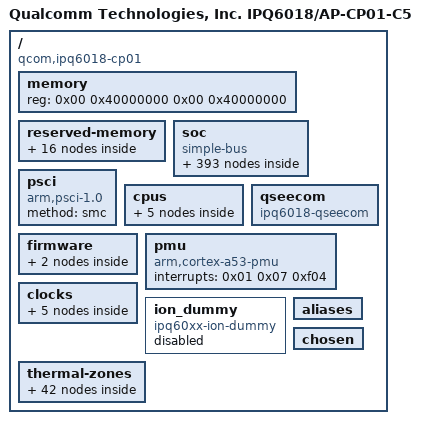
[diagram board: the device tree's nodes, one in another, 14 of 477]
/dts-v1/;

/ {
	model = "Qualcomm Technologies, Inc. IPQ6018/AP-CP01-C5";
	compatible = "qcom,ipq6018-cp01", "qcom,ipq6018";
	qcom,board-id = <0x08 0x00>;
	qcom,pmic-id = <0x00 0x00 0x00 0x00>;
	#address-cells = <0x02>;
	#size-cells = <0x02>;
	interrupt-parent = <0x01>;
	qcom,msm-id = <0x192 0x00 0x193 0x00>;

	memory {
		device_type = "memory";
		reg = <0x00 0x40000000 0x00 0x40000000>;
	};

	reserved-memory {
		#address-cells = <0x02>;
		#size-cells = <0x02>;
		ranges;

		nss@40000000 {
			no-map;
			reg = <0x00 0x40000000 0x00 0x1000000>;
		};

		uboot@4A100000 {
			no-map;
			reg = <0x00 0x4a100000 0x00 0x400000>;
		};

		sbl@4A500000 {
			no-map;
			reg = <0x00 0x4a500000 0x00 0x100000>;
		};

		tz@4A600000 {
			no-map;
			reg = <0x00 0x4a600000 0x00 0x400000>;
		};

		smem@4AA00000 {
			no-map;
			reg = <0x00 0x4aa00000 0x00 0x100000>;
			linux,phandle = <0x17>;
			phandle = <0x17>;
		};

		wcnss@4ab00000 {
			no-map;
			reg = <0x00 0x4ab00000 0x00 0x5500000>;
			linux,phandle = <0x1d>;
			phandle = <0x1d>;
		};

		q6_etr_dump@1 {
			no-map;
			reg = <0x00 0x50000000 0x00 0x100000>;
			linux,phandle = <0x1e>;
			phandle = <0x1e>;
		};

		m3_dump@50100000 {
			no-map;
			reg = <0x00 0x50100000 0x00 0x100000>;
		};

		rpm_msg_ram@0x60000 {
			no-map;
			reg = <0x00 0x60000 0x00 0x6000>;
			linux,phandle = <0x19>;
			phandle = <0x19>;
		};

		ramoops@b0000000 {
			no-map;
			reg = <0x00 0xb0000000 0x00 0x800000>;
		};

		device_last_ts@bf7fffef {
			no-map;
			reg = <0x00 0xbf7fffef 0x00 0x10>;
		};

		tzapp@49B00000 {
			no-map;
			reg = <0x00 0x49b00000 0x00 0x600000>;
		};

		qcn9000_pcie0@50200000 {
			no-map;
			reg = <0x00 0x50200000 0x00 0x2d00000>;
		};

		qcn9000_pcie1@52f00000 {
			no-map;
			reg = <0x00 0x52f00000 0x00 0x2d00000>;
		};

		dma_pool0@55c00000 {
			compatible = "shared-dma-pool";
			no-map;
			reg = <0x00 0x55c00000 0x00 0x1800000>;
			linux,phandle = <0x11>;
			phandle = <0x11>;
		};

		dma_pool1@57400000 {
			compatible = "shared-dma-pool";
			no-map;
			reg = <0x00 0x57400000 0x00 0x1800000>;
			linux,phandle = <0x12>;
			phandle = <0x12>;
		};
	};

	soc {
		#address-cells = <0x01>;
		#size-cells = <0x01>;
		ranges = <0x00 0x00 0x00 0xffffffff>;
		compatible = "simple-bus";

		wifi1@f00000 {
			compatible = "qcom,cnss-qcn9000";
			qcom,wlan-ramdump-dynamic = <0x400000>;
			status = "ok";
			mhi,max-channels = <0x1e>;
			mhi,timeout = <0x2710>;
			#address-cells = <0x01>;
			#size-cells = <0x00>;
			qrtr_node_id = <0x20>;
			qca,auto-restart;
			base-addr = "P ", "";
			m3-dump-addr = "RP", "";
			etr-addr = "R`", "";
			caldb-addr = "Rp", "";
			hremote-size = <0x2300000>;
			tgt-mem-mode = <0x00>;
			board_id = <0xa4>;
			caldb-size = <0x800000>;

			mhi_channels {

				mhi_chan@0 {
					reg = <0x00>;
					label = "LOOPBACK";
					mhi,num-elements = <0x20>;
					mhi,event-ring = <0x01>;
					mhi,chan-dir = <0x01>;
					mhi,data-type = <0x00>;
					mhi,doorbell-mode = <0x02>;
					mhi,ee = <0x14>;
				};

				mhi_chan@1 {
					reg = <0x01>;
					label = "LOOPBACK";
					mhi,num-elements = <0x20>;
					mhi,event-ring = <0x01>;
					mhi,chan-dir = <0x02>;
					mhi,data-type = <0x00>;
					mhi,doorbell-mode = <0x02>;
					mhi,ee = <0x14>;
				};

				mhi_chan@4 {
					reg = <0x04>;
					label = "DIAG";
					mhi,num-elements = <0x20>;
					mhi,event-ring = <0x01>;
					mhi,chan-dir = <0x01>;
					mhi,data-type = <0x00>;
					mhi,doorbell-mode = <0x02>;
					mhi,ee = <0x14>;
				};

				mhi_chan@5 {
					reg = <0x05>;
					label = "DIAG";
					mhi,num-elements = <0x20>;
					mhi,event-ring = <0x01>;
					mhi,chan-dir = <0x02>;
					mhi,data-type = <0x00>;
					mhi,doorbell-mode = <0x02>;
					mhi,ee = <0x14>;
				};

				mhi_chan@20 {
					reg = <0x14>;
					label = "IPCR";
					mhi,num-elements = <0x20>;
					mhi,event-ring = <0x01>;
					mhi,chan-dir = <0x01>;
					mhi,data-type = <0x01>;
					mhi,doorbell-mode = <0x02>;
					mhi,ee = <0x14>;
					mhi,auto-start;
				};

				mhi_chan@21 {
					reg = <0x15>;
					label = "IPCR";
					mhi,num-elements = <0x20>;
					mhi,event-ring = <0x01>;
					mhi,chan-dir = <0x02>;
					mhi,data-type = <0x00>;
					mhi,doorbell-mode = <0x02>;
					mhi,ee = <0x14>;
					mhi,auto-queue;
					mhi,auto-start;
				};
			};

			mhi_events {

				mhi_event@0 {
					mhi,num-elements = <0x20>;
					mhi,intmod = <0x01>;
					mhi,msi = <0x01>;
					mhi,priority = <0x01>;
					mhi,brstmode = <0x02>;
					mhi,data-type = <0x01>;
				};

				mhi_event@1 {
					mhi,num-elements = <0x100>;
					mhi,intmod = <0x01>;
					mhi,msi = <0x02>;
					mhi,priority = <0x01>;
					mhi,brstmode = <0x02>;
				};
			};

			mhi_devices {

				mhi_qrtr {
					mhi,chan = "IPCR";
					qcom,net-id = <0x00>;
				};
			};
		};

		wifi2@f00000 {
			compatible = "qcom,cnss-qcn9000";
			qcom,wlan-ramdump-dynamic = <0x400000>;
			status = "ok";
			mhi,max-channels = <0x1e>;
			mhi,timeout = <0x2710>;
			#address-cells = <0x01>;
			#size-cells = <0x00>;
			qrtr_node_id = <0x21>;
			qca,auto-restart;
			base-addr = <0x52f00000>;
			m3-dump-addr = "U ", "";
			etr-addr = "U0", "";
			caldb-addr = "U@", "";
			hremote-size = <0x2300000>;
			tgt-mem-mode = <0x00>;
			board_id = <0xa4>;
			caldb-size = <0x800000>;

			mhi_channels {

				mhi_chan@0 {
					reg = <0x00>;
					label = "LOOPBACK";
					mhi,num-elements = <0x20>;
					mhi,event-ring = <0x01>;
					mhi,chan-dir = <0x01>;
					mhi,data-type = <0x00>;
					mhi,doorbell-mode = <0x02>;
					mhi,ee = <0x14>;
				};

				mhi_chan@1 {
					reg = <0x01>;
					label = "LOOPBACK";
					mhi,num-elements = <0x20>;
					mhi,event-ring = <0x01>;
					mhi,chan-dir = <0x02>;
					mhi,data-type = <0x00>;
					mhi,doorbell-mode = <0x02>;
					mhi,ee = <0x14>;
				};

				mhi_chan@4 {
					reg = <0x04>;
					label = "DIAG";
					mhi,num-elements = <0x20>;
					mhi,event-ring = <0x01>;
					mhi,chan-dir = <0x01>;
					mhi,data-type = <0x00>;
					mhi,doorbell-mode = <0x02>;
					mhi,ee = <0x14>;
				};

				mhi_chan@5 {
					reg = <0x05>;
					label = "DIAG";
					mhi,num-elements = <0x20>;
					mhi,event-ring = <0x01>;
					mhi,chan-dir = <0x02>;
					mhi,data-type = <0x00>;
					mhi,doorbell-mode = <0x02>;
					mhi,ee = <0x14>;
				};

				mhi_chan@20 {
					reg = <0x14>;
					label = "IPCR";
					mhi,num-elements = <0x20>;
					mhi,event-ring = <0x01>;
					mhi,chan-dir = <0x01>;
					mhi,data-type = <0x01>;
					mhi,doorbell-mode = <0x02>;
					mhi,ee = <0x14>;
					mhi,auto-start;
				};

				mhi_chan@21 {
					reg = <0x15>;
					label = "IPCR";
					mhi,num-elements = <0x20>;
					mhi,event-ring = <0x01>;
					mhi,chan-dir = <0x02>;
					mhi,data-type = <0x00>;
					mhi,doorbell-mode = <0x02>;
					mhi,ee = <0x14>;
					mhi,auto-queue;
					mhi,auto-start;
				};
			};

			mhi_events {

				mhi_event@0 {
					mhi,num-elements = <0x20>;
					mhi,intmod = <0x01>;
					mhi,msi = <0x01>;
					mhi,priority = <0x01>;
					mhi,brstmode = <0x02>;
					mhi,data-type = <0x01>;
				};

				mhi_event@1 {
					mhi,num-elements = <0x100>;
					mhi,intmod = <0x01>;
					mhi,msi = <0x02>;
					mhi,priority = <0x01>;
					mhi,brstmode = <0x02>;
				};
			};

			mhi_devices {

				mhi_qrtr {
					mhi,chan = "IPCR";
					qcom,net-id = <0x00>;
				};
			};
		};

		interrupt-controller@b000000 {
			compatible = "qcom,msm-qgic2";
			interrupt-controller;
			#interrupt-cells = <0x03>;
			reg = <0xb000000 0x1000 0xb002000 0x1000>;
			linux,phandle = <0x01>;
			phandle = <0x01>;
		};

		timer {
			compatible = "arm,armv8-timer";
			interrupts = <0x01 0x02 0xf08 0x01 0x03 0xf08 0x01 0x04 0xf08 0x01 0x01 0xf08>;
			clock-frequency = <0x16e3600>;
			always-on;
		};

		gcc@1800000 {
			compatible = "qcom,gcc-ipq6018";
			reg = <0x1800000 0x80000>;
			#clock-cells = <0x01>;
			#reset-cells = <0x01>;
			linux,phandle = <0x03>;
			phandle = <0x03>;
		};

		qcom,apss_clk@b111000 {
			compatible = "qcom,apss-ipq6018";
			reg = <0xb111000 0x6000>;
			#clock-cells = <0x01>;
			#reset-cells = <0x01>;
			linux,phandle = <0x58>;
			phandle = <0x58>;
		};

		arm,smmu@1E00000 {
			compatible = "arm,smmu-v2";
			reg = <0x1e00000 0x40000>;
			#iommu-cells = <0x01>;
			#global-interrupts = <0x01>;
			qcom,skip-init;
			interrupts = <0x00 0x29 0x04 0x00 0x46 0x04 0x00 0x47 0x04 0x00 0x49 0x04 0x00 0xf0 0x04 0x00 0xf1 0x04 0x00 0xf2 0x04 0x00 0xf5 0x04 0x00 0xf6 0x04 0x00 0xf7 0x04 0x00 0xf8 0x04 0x00 0xf9 0x04 0x00 0xfa 0x04 0x00 0xfb 0x04 0x00 0xfc 0x04 0x00 0xfd 0x04 0x00 0xfe 0x04 0x00 0xff 0x04 0x00 0x35 0x04 0x00 0x36 0x04 0x00 0x3a 0x04 0x00 0x3c 0x04 0x00 0x3d 0x04 0x00 0x4c 0x04 0x00 0x4d 0x04 0x00 0x50 0x04 0x00 0x5e 0x04 0x00 0x65 0x04 0x00 0x66 0x04 0x00 0x67 0x04 0x00 0x68 0x04 0x00 0x69 0x04 0x00 0x6a 0x04>;
			status = "disabled";
			linux,phandle = <0x02>;
			phandle = <0x02>;
		};

		qcom,msm-adsprpc-mem {
			compatible = "qcom,msm-adsprpc-mem-region";
			status = "disabled";
		};

		qcom,msm_fastrpc {
			compatible = "qcom,msm-fastrpc-compute";
			qcom,rpc-latency-us = <0x263>;
			qcom,fastrpc-adsp-audio-pdr;
			qcom,fastrpc-adsp-sensors-pdr;
			qcom,fastrpc-legacy-remote-heap;
			status = "disabled";

			qcom,msm_fastrpc_compute_cb1 {
				compatible = "qcom,msm-fastrpc-compute-cb";
				label = "adsprpc-smd";
				iommus = <0x02 0x1004>;
			};

			qcom,msm_fastrpc_compute_cb2 {
				compatible = "qcom,msm-fastrpc-compute-cb";
				label = "adsprpc-smd";
				iommus = <0x02 0x1005>;
			};

			qcom,msm_fastrpc_compute_cb3 {
				compatible = "qcom,msm-fastrpc-compute-cb";
				label = "adsprpc-smd";
				iommus = <0x02 0x1006>;
			};

			qcom,msm_fastrpc_compute_cb4 {
				compatible = "qcom,msm-fastrpc-compute-cb";
				label = "adsprpc-smd";
				iommus = <0x02 0x1007>;
			};

			qcom,msm_fastrpc_compute_cb5 {
				compatible = "qcom,msm-fastrpc-compute-cb";
				label = "adsprpc-smd";
				iommus = <0x02 0x1008>;
			};

			qcom,msm_fastrpc_compute_cb6 {
				compatible = "qcom,msm-fastrpc-compute-cb";
				label = "adsprpc-smd";
				iommus = <0x02 0x1009>;
			};

			qcom,msm_fastrpc_compute_cb7 {
				compatible = "qcom,msm-fastrpc-compute-cb";
				label = "adsprpc-smd";
				iommus = <0x02 0x100a>;
			};

			qcom,msm_fastrpc_compute_cb8 {
				compatible = "qcom,msm-fastrpc-compute-cb";
				label = "adsprpc-smd";
				iommus = <0x02 0x100b>;
			};
		};

		serial@78b3000 {
			compatible = "qcom,msm-uartdm-v1.4", "qcom,msm-uartdm";
			reg = <0x78b3000 0x200>;
			interrupts = <0x00 0x134 0x04>;
			clocks = <0x03 0x54 0x03 0x43>;
			clock-names = "core", "iface";
			status = "disabled";
		};

		serial@78af000 {
			compatible = "qcom,msm-uartdm-v1.4", "qcom,msm-uartdm";
			reg = <0x78af000 0x200>;
			interrupts = <0x00 0x6b 0x04>;
			clocks = <0x03 0x50 0x03 0x43>;
			clock-names = "core", "iface";
			status = "disabled";
		};

		serial@78b0000 {
			compatible = "qcom,msm-uartdm-v1.4", "qcom,msm-uartdm";
			reg = <0x78b0000 0x200>;
			interrupts = <0x00 0x6c 0x04>;
			clocks = <0x03 0x51 0x03 0x43>;
			clock-names = "core", "iface";
			status = "ok";
			pinctrl-0 = <0x04>;
			pinctrl-names = "default";
			dmas = <0x05 0x02 0x05 0x03>;
			dma-names = "tx", "rx";
		};

		serial@78b1000 {
			compatible = "qcom,msm-uartdm-v1.4", "qcom,msm-uartdm";
			reg = <0x78b1000 0x200>;
			interrupts = <0x00 0x132 0x04>;
			clocks = <0x03 0x52 0x03 0x43>;
			clock-names = "core", "iface";
			status = "ok";
			pinctrl-0 = <0x06>;
			pinctrl-names = "default";
		};

		serial@78b2000 {
			compatible = "qcom,msm-uartdm-v1.4", "qcom,msm-uartdm";
			reg = <0x78b2000 0x200>;
			interrupts = <0x00 0x133 0x04>;
			clocks = <0x03 0x53 0x03 0x43>;
			clock-names = "core", "iface";
			status = "ok";
			pinctrl-0 = <0x07>;
			pinctrl-names = "default";
		};

		qrng@e1000 {
			compatible = "qcom,prng-ipq807x";
			reg = <0xe3000 0x1000>;
			clocks = <0x03 0x88>;
			clock-names = "core";
			status = "ok";
		};

		dma@704000 {
			compatible = "qcom,bam-v1.7.0";
			reg = <0x704000 0x20000>;
			interrupts = <0x00 0xcf 0x00>;
			clocks = <0x03 0x56>;
			clock-names = "bam_clk";
			#dma-cells = <0x01>;
			qcom,ee = <0x01>;
			qcom,controlled-remotely = <0x01>;
			qcom,config-pipe-trust-reg = <0x00>;
			linux,phandle = <0x08>;
			phandle = <0x08>;
		};

		crypto@73a000 {
			compatible = "qcom,crypto-v5.1";
			reg = <0x73a000 0x6000>;
			clocks = <0x03 0x56 0x03 0x57 0x03 0x58>;
			clock-names = "iface", "bus", "core";
			dmas = <0x08 0x02 0x08 0x03>;
			dma-names = "rx", "tx";
		};

		qcom_mdss_qpic@7980000 {
			compatible = "qcom,mdss_qpic";
			reg = <0x7980000 0x24000>;
			interrupts = <0x00 0x97 0x00>;
			clocks = <0x03 0x8a 0x03 0x89>;
			clock-names = "core", "aon";
			dmas = <0x09 0x06>;
			dma-names = "chan";
			status = "ok";
		};

		qcom_mdss_qpic_panel {
			compatible = "qcom,mdss-qpic-panel";
			label = "qpic lcd panel";
			qcom,mdss-pan-res = <0x320 0x1e0>;
			qcom,mdss-pan-bpp = <0x12>;
			qcom,refresh_rate = <0x3c>;
			status = "ok";
		};

		ssphy@78000 {
			compatible = "qcom,usb-ssphy-qmp";
			reg = <0x78000 0x45c 0x193f244 0x04 0x8af8800 0x100 0x7e000 0x18>;
			reg-names = "qmp_phy_base", "vls_clamp_reg", "qscratch_base", "ahb2phy_base";
			qcom,qmp-phy-init-seq = <0xac 0x14 0x1a 0x00 0x34 0x08 0x08 0x00 0x174 0x30 0x30 0x00 0x3c 0x06 0x06 0x00 0xb4 0x00 0x00 0x00 0xb8 0x08 0x08 0x00 0x194 0x06 0x06 0x3e8 0x19c 0x01 0x01 0x00 0x178 0x00 0x00 0x00 0xd0 0x68 0x68 0x00 0xdc 0xab 0xab 0x00 0xe0 0xaa 0xaa 0x00 0xe4 0x02 0x02 0x00 0x78 0x09 0x09 0x00 0x84 0x16 0x16 0x00 0x90 0x28 0x28 0x00 0x108 0xa0 0xa0 0x00 0x10c 0x00 0x00 0x00 0x184 0x0a 0x0a 0x00 0x4c 0xaa 0xaa 0x00 0x50 0x29 0x29 0x00 0x54 0x00 0x00 0x00 0xc8 0x00 0x00 0x00 0x18c 0x00 0x00 0x00 0xcc 0x00 0x00 0x00 0x128 0x00 0x00 0x00 0x0c 0x0a 0x0a 0x00 0x10 0x01 0x01 0x00 0x1c 0x7d 0x7d 0x00 0x20 0x01 0x01 0x00 0x14 0x00 0x00 0x00 0x18 0x00 0x00 0x00 0x24 0x0a 0x0a 0x00 0x28 0x05 0x05 0x00 0x48 0x0f 0x0f 0x00 0x70 0x0f 0x0f 0x00 0x100 0x80 0x80 0x00 0x440 0x0b 0x0b 0x00 0x4d8 0x02 0x02 0x00 0x4dc 0x6c 0x6c 0x00 0x4e0 0xbb 0xb8 0x00 0x508 0x77 0x77 0x00 0x50c 0x80 0x80 0x00 0x514 0x03 0x03 0x00 0x51c 0x16 0x16 0x00 0x448 0x75 0x75 0x00 0x454 0x00 0x00 0x00 0x40c 0x0a 0x0a 0x00 0x41c 0x06 0x06 0x00 0x510 0x00 0x00 0x00 0x268 0x45 0x45 0x00 0x2ac 0x12 0x12 0x00 0x294 0x06 0x06 0x00 0x254 0x00 0x00 0x00 0x8c8 0x83 0x83 0x00 0x8c4 0x02 0x02 0x00 0x8cc 0x09 0x09 0x00 0x8d0 0xa2 0xa2 0x00 0x8d4 0x85 0x85 0x00 0x880 0xd1 0xd1 0x00 0x884 0x1f 0x1f 0x00 0x888 0x47 0x47 0x00 0x80c 0x9f 0x9f 0x00 0x824 0x17 0x17 0x00 0x828 0x0f 0x0f 0x00 0x8b8 0x75 0x75 0x00 0x8bc 0x13 0x13 0x00 0x8b0 0x86 0x86 0x00 0x8a0 0x04 0x04 0x00 0x88c 0x44 0x44 0x00 0x870 0xe7 0xe7 0x00 0x874 0x03 0x03 0x00 0x878 0x40 0x40 0x00 0x87c 0x00 0x00 0x00 0x9d8 0x88 0x88 0x00 0xffffffff 0xffffffff 0x00 0x00>;
			qcom,qmp-phy-reg-offset = <0x988 0x98c 0x990 0x994 0x974 0x8d8 0x8dc 0x804 0x800 0x808>;
			clocks = <0x03 0x9d 0x03 0xa1>;
			clock-names = "aux_clk", "pipe_clk";
			resets = <0x03 0x27 0x03 0x28>;
			reset-names = "usb3_phy_reset", "usb3phy_phy_reset";
			status = "ok";
			linux,phandle = <0x0c>;
			phandle = <0x0c>;
		};

		qusb@79000 {
			compatible = "qcom,qusb2phy";
			reg = <0x79000 0x180 0x8af8800 0x400 0x1841030 0x04 0x8a0c12c 0x04>;
			reg-names = "qusb_phy_base", "qscratch_base", "ref_clk_addr", "usb3_guctl_addr";
			qcom,qusb-phy-init-seq = <0x14 0x00 0xf8 0x80 0xb3 0x84 0x83 0x88 0xc0 0x8c 0x30 0x08 0x79 0x0c 0x21 0x10 0x00 0x90 0x00 0x18 0x14 0x9c 0x80 0x04 0x9f 0x1c>;
			phy_type = "utmi";
			resets = <0x03 0x2b>;
			reset-names = "usb2_phy_reset";
			status = "ok";
			linux,phandle = <0x0b>;
			phandle = <0x0b>;
		};

		qusb@59000 {
			compatible = "qcom,qusb2phy";
			reg = <0x59000 0x180 0x70f8800 0x400 0x1841030 0x04 0x700c12c 0x04>;
			reg-names = "qusb_phy_base", "qscratch_base", "ref_clk_addr", "usb3_guctl_addr";
			qcom,qusb-phy-init-seq = <0x14 0x00 0xf8 0x80 0xb3 0x84 0x83 0x88 0xc0 0x8c 0x30 0x08 0x79 0x0c 0x21 0x10 0x00 0x90 0x00 0x18 0x14 0x9c 0x80 0x04 0x9f 0x1c>;
			phy_type = "utmi";
			resets = <0x03 0x2c>;
			reset-names = "usb2_phy_reset";
			status = "ok";
			linux,phandle = <0x0f>;
			phandle = <0x0f>;
		};

		dbm@0x8AF8000 {
			compatible = "qcom,usb-dbm-1p5";
			reg = <0x8af8000 0x300>;
			qcom,reset-ep-after-lpm-resume;
			linux,phandle = <0x0a>;
			phandle = <0x0a>;
		};

		usb3@8A00000 {
			compatible = "qcom,ipq6018-dwc3";
			#address-cells = <0x01>;
			#size-cells = <0x01>;
			ranges;
			reg = <0x8af8800 0x100 0x8a00000 0xcd00>;
			reg-names = "qscratch_base", "dwc3_base";
			clocks = <0x03 0xb9 0x03 0xba 0x03 0x9e 0x03 0xa2 0x03 0x9f 0x03 0xa0 0x03 0x9d 0x03 0xa1>;
			clock-names = "snoc_bus_timeout2", "sys_noc_axi", "master", "sleep", "mock_utmi", "cfg_ahb_clk", "aux_clk", "pipe_clk";
			assigned-clocks = <0x03 0xba 0x03 0x9e 0x03 0x9f>;
			assigned-clock-rates = <0x7f27450 0x7f27450 0x16e3600>;
			qca,host = <0x01>;
			qcom,usb-dbm = <0x0a>;
			status = "ok";

			dwc3@8A00000 {
				compatible = "snps,dwc3";
				reg = <0x8a00000 0xcd00>;
				interrupts = <0x00 0x8c 0x00>;
				usb-phy = <0x0b 0x0c>;
				snps,dis_ep_cache_eviction;
				tx-fifo-resize;
				snps,usb3-u1u2-disable;
				snps,nominal-elastic-buffer;
				snps,is-utmi-l1-suspend;
				snps,hird-threshold = [00];
				snps,dis_u2_susphy_quirk;
				snps,dis_u3_susphy_quirk;
				snps,quirk-ref-clock-adjustment = <0xa87f0>;
				snps,quirk-ref-clock-period = <0x29>;
				dr_mode = "host";
			};
		};

		qcom,usbbam@8B04000 {
			compatible = "qcom,usb-bam-msm";
			reg = <0x8b04000 0x17000>;
			interrupt-parent = <0x01>;
			interrupts = <0x00 0x87 0x00>;
			qcom,bam-type = <0x00>;
			qcom,usb-bam-fifo-baseaddr = <0x4a100000>;
			qcom,usb-bam-num-pipes = <0x04>;
			qcom,ignore-core-reset-ack;
			qcom,disable-clk-gating;
			qcom,usb-bam-override-threshold = <0x4001>;
			qcom,usb-bam-max-mbps-highspeed = <0x190>;
			qcom,usb-bam-max-mbps-superspeed = <0xe10>;
			qcom,reset-bam-on-connect;

			qcom,pipe0 {
				label = "ssusb-qdss-in-0";
				qcom,usb-bam-mem-type = <0x02>;
				qcom,dir = <0x01>;
				qcom,pipe-num = <0x00>;
				qcom,peer-bam = <0x00>;
				qcom,peer-bam-physical-address = <0x6064000>;
				qcom,src-bam-pipe-index = <0x00>;
				qcom,dst-bam-pipe-index = <0x00>;
				qcom,data-fifo-offset = <0x00>;
				qcom,data-fifo-size = <0xe00>;
				qcom,descriptor-fifo-offset = <0xe00>;
				qcom,descriptor-fifo-size = <0x200>;
			};
		};

		extcon_usb {
			compatible = "linux,extcon-usb-gpio";
			status = "disabled";
			pinctrl-0 = <0x0d>;
			pinctrl-names = "default";
			id-gpio = <0x0e 0x1a 0x01>;
		};

		usb2@7000000 {
			compatible = "qcom,ipq6018-dwc3";
			#address-cells = <0x01>;
			#size-cells = <0x01>;
			ranges;
			reg = <0x70f8800 0x100 0x7000000 0xcd00>;
			reg-names = "qscratch_base", "dwc3_base";
			clocks = <0x03 0xa3 0x03 0xa6 0x03 0xa4 0x03 0xa5>;
			clock-names = "master", "sleep", "mock_utmi", "cfg_ahb_clk";
			assigned-clocks = <0x03 0xa3 0x03 0xa4>;
			assigned-clock-rates = <0x7f27450 0x16e3600>;
			qca,host = <0x01>;
			status = "ok";

			dwc3@7000000 {
				compatible = "snps,dwc3";
				reg = <0x7000000 0xcd00>;
				interrupts = <0x00 0x63 0x00>;
				usb-phy = <0x0f>;
				snps,dis_ep_cache_eviction;
				tx-fifo-resize;
				snps,usb3-u1u2-disable;
				snps,nominal-elastic-buffer;
				snps,is-utmi-l1-suspend;
				snps,hird-threshold = [00];
				snps,dis_u2_susphy_quirk;
				snps,dis_u3_susphy_quirk;
				snps,quirk-ref-clock-adjustment = <0xa87f0>;
				snps,quirk-ref-clock-period = <0x29>;
				dr_mode = "host";
			};
		};

		phy@84000 {
			compatible = "qca,pcie-qmp-phy-gen3";
			reg = <0x84000 0x1000>;
			phy-type = "gen3";
			qcom,qmp-pcie-phy-init-seq = <0x840 0x03 0x1c 0x7d 0x20 0x01 0x24 0x0a 0x28 0x05 0x2c 0x08 0x30 0x04 0x3c 0x18 0x40 0x90 0x44 0x02 0x48 0x07 0x50 0x0f 0x54 0xd4 0x58 0x14 0x60 0xaa 0x64 0x29 0x74 0x0f 0xffffffff 0x01 0x80 0x09 0x84 0x09 0x88 0x16 0x8c 0x16 0x90 0x28 0x94 0x28 0xa4 0x01 0xa8 0x08 0xb0 0x20 0xc4 0x42 0xcc 0x68 0xd0 0x53 0xd8 0xab 0xdc 0xaa 0xe0 0x02 0xe4 0x55 0xe8 0x55 0xec 0x05 0x100 0xa0 0x108 0xa0 0x124 0x24 0x128 0x02 0x12c 0xb4 0x130 0x03 0x16c 0x32 0x170 0x01 0x184 0x00 0x18c 0x06 0x194 0x05 0x1b4 0x08 0x23c 0x02 0x284 0x06 0x29c 0x12 0x408 0x0c 0x414 0x02 0x434 0x7f 0x444 0x70 0x4ec 0x61 0x4f0 0x04 0x4f4 0x1e 0x4f8 0xc0 0x4fc 0x00 0x510 0x73 0x514 0x80 0x518 0x1c 0x51c 0x03 0x524 0x14 0x570 0xf0 0x574 0x01 0x578 0x2f 0x57c 0xd3 0x580 0x40 0x584 0x01 0x588 0x02 0x58c 0xc8 0x590 0x09 0x594 0xb1 0x598 0x00 0x59c 0x02 0x5a0 0xc8 0x5a4 0x09 0x5a8 0xb1 0x5b4 0x04 0x898 0x01 0x8dc 0x0d 0x96c 0x10 0x988 0xaa 0x9a4 0x01 0x9d8 0x01 0x9ec 0x01 0xc0c 0x0d 0xc14 0x07 0xc1c 0xc1 0xc40 0x01 0xc48 0x01 0xc90 0x00 0xca0 0x11 0xcbc 0x00 0xce0 0x58 0x800 0x00 0x844 0x03>;
			#phy-cells = <0x00>;
			clocks = <0x03 0x87>;
			clock-names = "pipe_clk";
			resets = <0x03 0x45 0x03 0x46>;
			reset-names = "phy", "phy_phy";
			status = "ok";
			linux,phandle = <0x10>;
			phandle = <0x10>;
		};

		pci@20000000 {
			compatible = "qcom,pcie-ipq6018";
			reg = <0x20000000 0xf1d 0x20000f20 0xa8 0x20001000 0x1000 0x80000 0x2000 0x20100000 0x1000>;
			reg-names = "dbi", "elbi", "dm_iatu", "parf", "config";
			device_type = "pci";
			linux,pci-domain = <0x00>;
			bus-range = <0x00 0xff>;
			num-lanes = <0x01>;
			#address-cells = <0x03>;
			#size-cells = <0x02>;
			phys = <0x10>;
			phy-names = "pciephy";
			ranges = <0x81000000 0x00 0x20200000 0x20200000 0x00 0x100000 0x82000000 0x00 0x20300000 0x20300000 0x00 0x10000000>;
			interrupts = <0x00 0x34 0x00 0x00 0x1a0 0x00 0x00 0x1a1 0x00 0x00 0x1a2 0x00 0x00 0x1a3 0x00 0x00 0x1a4 0x00 0x00 0x1a5 0x00 0x00 0x1a6 0x00 0x00 0x1a7 0x00 0x00 0x1a8 0x00 0x00 0x1a9 0x00 0x00 0x1aa 0x00 0x00 0x1ab 0x00 0x00 0x1ac 0x00 0x00 0x1ad 0x00 0x00 0x1ae 0x00 0x00 0x1af 0x00 0x00 0x1b0 0x00 0x00 0x1b1 0x00 0x00 0x1b2 0x00 0x00 0x1b3 0x00 0x00 0x1b4 0x00 0x00 0x1b5 0x00 0x00 0x1b6 0x00 0x00 0x1b7 0x00 0x00 0x1b8 0x00 0x00 0x1b9 0x00 0x00 0x1ba 0x00 0x00 0x1bb 0x00 0x00 0x1bc 0x00 0x00 0x1bd 0x00 0x00 0x1be 0x00 0x00 0x1bf 0x00>;
			interrupt-names = "msi", "msi_0", "msi_1", "msi_2", "msi_3", "msi_4", "msi_5", "msi_6", "msi_7", "msi_8", "msi_9", "msi_10", "msi_11", "msi_12", "msi_13", "msi_14", "msi_15", "msi_16", "msi_17", "msi_18", "msi_19", "msi_20", "msi_21", "msi_22", "msi_23", "msi_24", "msi_25", "msi_26", "msi_27", "msi_28", "msi_29", "msi_30", "msi_31";
			#interrupt-cells = <0x01>;
			interrupt-map-mask = <0x00 0x00 0x00 0x07>;
			interrupt-map = <0x00 0x00 0x00 0x01 0x01 0x00 0x4b 0x04 0x00 0x00 0x00 0x02 0x01 0x00 0x4e 0x04 0x00 0x00 0x00 0x03 0x01 0x00 0x4f 0x04 0x00 0x00 0x00 0x04 0x01 0x00 0x53 0x04>;
			clocks = <0x03 0xbb 0x03 0x85 0x03 0x86 0x03 0x83 0x03 0x84 0x03 0xc6 0x03 0xc7>;
			clock-names = "sys_noc", "axi_m", "axi_s", "ahb", "aux", "axi_bridge", "rchng";
			resets = <0x03 0x60 0x03 0x61 0x03 0x62 0x03 0x63 0x03 0x64 0x03 0x65 0x03 0x66 0x03 0x67>;
			reset-names = "pipe", "sleep", "sticky", "axi_m", "axi_s", "ahb", "axi_m_sticky", "axi_s_sticky";
			perst-gpio = <0x0e 0x3c 0x01>;
			status = "ok";
			qcom,msi-gicm-addr = <0xb00a040>;
			qcom,msi-gicm-base = <0x1c0>;

			pcie0_rp {
				reg = <0x00 0x00 0x00 0x00 0x00>;
				status = "ok";
				device_type = "pci";

				pcie_port_1 {
					reg = <0x00 0x00 0x00 0x00 0x00>;
					device_type = "pci";
					status = "ok";

					pcie_slot1 {
						reg = <0x800 0x00 0x00 0x00 0x00>;
						device_type = "pci";
						status = "ok";

						qcom,mhi@0 {
							reg = <0x00 0x00 0x00 0x00 0x00>;
							qrtr_instance_id = <0x20>;
							memory-region = <0x11>;
						};
					};

					pcie_slot2 {
						reg = <0x1000 0x00 0x00 0x00 0x00>;
						device_type = "pci";
						status = "ok";

						qcom,mhi@1 {
							reg = <0x00 0x00 0x00 0x00 0x00>;
							qrtr_instance_id = <0x21>;
							memory-region = <0x12>;
						};
					};
				};
			};
		};

		qcom,diag@0 {
			compatible = "qcom,diag";
			status = "ok";
		};

		qcom,gadget_diag@0 {
			compatible = "qcom,gadget-diag";
			status = "disabled";
		};

		dma@7884000 {
			compatible = "qcom,bam-v1.7.0";
			reg = <0x7884000 0x2b000>;
			interrupts = <0x00 0xee 0x00>;
			clocks = <0x03 0x43>;
			clock-names = "bam_clk";
			#dma-cells = <0x01>;
			qcom,ee = <0x00>;
			linux,phandle = <0x05>;
			phandle = <0x05>;
		};

		i2c@78b6000 {
			compatible = "qcom,i2c-qup-v2.2.1";
			#address-cells = <0x01>;
			#size-cells = <0x00>;
			reg = <0x78b6000 0x600>;
			interrupts = <0x00 0x60 0x04>;
			clocks = <0x03 0x43 0x03 0x46>;
			clock-names = "iface", "core";
			clock-frequency = <0x61a80>;
			dmas = <0x05 0x0f 0x05 0x0e>;
			dma-names = "rx", "tx";
			status = "disabled";
		};

		i2c@78b7000 {
			compatible = "qcom,i2c-qup-v2.2.1";
			#address-cells = <0x01>;
			#size-cells = <0x00>;
			reg = <0x78b7000 0x600>;
			interrupts = <0x00 0x61 0x04>;
			clocks = <0x03 0x43 0x03 0x48>;
			clock-names = "iface", "core";
			clock-frequency = <0x61a80>;
			dmas = <0x05 0x11 0x05 0x10>;
			dma-names = "rx", "tx";
			status = "disabled";
		};

		spi@78b5000 {
			compatible = "qcom,spi-qup-v2.2.1";
			#address-cells = <0x01>;
			#size-cells = <0x00>;
			reg = <0x78b5000 0x600>;
			interrupts = <0x00 0x5f 0x00>;
			spi-max-frequency = <0x2faf080>;
			clocks = <0x03 0x45 0x03 0x43>;
			clock-names = "core", "iface";
			dmas = <0x05 0x0c 0x05 0x0d>;
			dma-names = "tx", "rx";
			status = "ok";
			pinctrl-0 = <0x13>;
			pinctrl-names = "default";
			cs-select = <0x00>;

			m25p80@0 {
				#address-cells = <0x01>;
				#size-cells = <0x01>;
				reg = <0x00>;
				compatible = "n25q128a11";
				linux,modalias = "m25p80", "n25q128a11";
				spi-max-frequency = <0x2faf080>;
				use-default-sizes;
			};
		};

		spi@78b6000 {
			compatible = "qcom,spi-qup-v2.2.1";
			#address-cells = <0x01>;
			#size-cells = <0x00>;
			reg = <0x78b6000 0x600>;
			interrupts = <0x00 0x60 0x00>;
			spi-max-frequency = <0x2faf080>;
			clocks = <0x03 0x47 0x03 0x43>;
			clock-names = "core", "iface";
			dmas = <0x05 0x0e 0x05 0x0f>;
			dma-names = "tx", "rx";
			status = "disabled";
		};

		spi@78b9000 {
			compatible = "qcom,spi-qup-v2.2.1";
			#address-cells = <0x01>;
			#size-cells = <0x00>;
			reg = <0x78b9000 0x600>;
			interrupts = <0x00 0x12b 0x04>;
			spi-max-frequency = <0x2faf080>;
			clocks = <0x03 0x4d 0x03 0x43>;
			clock-names = "core", "iface";
			dmas = <0x05 0x14 0x05 0x15>;
			dma-names = "tx", "rx";
			status = "ok";
			pinctrl-0 = <0x14>;
			pinctrl-names = "default";
			cs-select = <0x00>;

			tpm_tis_spi@1 {
				compatible = "tcg,tpm_spi_tis";
				reg = <0x00>;
				spi-max-frequency = <0xf42400>;
			};
		};

		pwm {
			compatible = "qca,ipq6018-pwm";
			reg = <0x1941010 0x20>;
			clocks = <0x03 0xc1>;
			clock-names = "core";
			src-freq = <0x5f5e100>;
			pwm-base-index = <0x00>;
			used-pwm-indices = <0x01 0x01 0x01 0x01>;
			status = "disabled";
		};

		dcc@b3000 {
			compatible = "qca,dcc";
			status = "ok";
			reg = <0xb3000 0x1000 0xb4000 0x800 0x4a2000 0x08>;
			reg-names = "dcc-base", "dcc-ram-base", "gcnt_lo_hi";
			clocks = <0x03 0xc4>;
			clock-names = "dcc_clk";
			no_xpu_support;
			qca,save-reg;
		};

		syscon@1905000 {
			compatible = "syscon";
			reg = <0x1905000 0x8000>;
			linux,phandle = <0x15>;
			phandle = <0x15>;
		};

		hwlock@1905000 {
			compatible = "qcom,tcsr-mutex";
			syscon = <0x15 0x00 0x80>;
			#hwlock-cells = <0x01>;
			linux,phandle = <0x18>;
			phandle = <0x18>;
		};

		syscon@1945000 {
			compatible = "syscon";
			reg = <0x1945000 0xe000>;
			linux,phandle = <0x29>;
			phandle = <0x29>;
		};

		mailbox@b111000 {
			compatible = "qcom,msm8996-apcs-hmss-global";
			qcom,ipc = <0x16 0x08 0x08>;
			#mbox-cells = <0x01>;
			linux,phandle = <0x2a>;
			phandle = <0x2a>;
		};

		mailboxlpass@b111000 {
			compatible = "qcom,msm8996-apcs-hmss-global";
			qcom,ipc = <0x16 0x08 0x17>;
			#mbox-cells = <0x01>;
			linux,phandle = <0x2b>;
			phandle = <0x2b>;
		};

		mailboxrpm@b111000 {
			compatible = "qcom,msm8996-apcs-hmss-global";
			qcom,ipc = <0x16 0x08 0x00>;
			#mbox-cells = <0x01>;
			linux,phandle = <0x1a>;
			phandle = <0x1a>;
		};

		qcom,smem@4AA00000 {
			compatible = "qcom,smem";
			memory-region = <0x17>;
			hwlocks = <0x18 0x00>;
		};

		qcom,glink-smem-native-xprt-modem@4AA00000 {
			compatible = "qcom,glink-smem-native-xprt";
			reg = <0x4aa00000 0x100000 0xb111008 0x04>;
			reg-names = "smem", "irq-reg-base";
			qcom,irq-mask = <0x100>;
			interrupts = <0x00 0x141 0x01>;
			label = "mpss";
			qcom,subsys-id = <0x01>;
			smem-entry = <0x1de 0x1df 0x1e0>;
			smem-entry-names = "ch", "tx_fifo", "rx_fifo";
		};

		qcom,glink-smem-native-xprt-adsp@4AA00000 {
			compatible = "qcom,glink-smem-native-xprt";
			reg = <0x4aa00000 0x100000 0xb111008 0x04>;
			reg-names = "smem", "irq-reg-base";
			qcom,irq-mask = <0x800000>;
			interrupts = <0x00 0x18 0x01>;
			label = "adsp";
			qcom,subsys-id = <0x02>;
			smem-entry = <0x1de 0x1df 0x1e0>;
			smem-entry-names = "ch", "tx_fifo", "rx_fifo";
			status = "disabled";
		};

		qcom,glink-rpm-native-xprt@60000 {
			compatible = "qcom,glink-rpm-native-xprt";
			reg = <0x60000 0x6000 0xb111008 0x04>;
			reg-names = "msgram", "irq-reg-base";
			qcom,irq-mask = <0x01>;
			interrupts = <0x00 0xa8 0x01>;
			label = "rpm";
			qcom,subsys-id = <0x06>;
			status = "ok";
		};

		qcom,rpmsg-rpm@60000 {
			compatible = "qcom,glink-rpm";
			qcom,rpm-msg-ram = <0x19>;
			interrupts = <0x00 0xa8 0x01>;
			label = "rpm";
			qcom,subsys-id = <0x06>;
			mboxes = <0x1a 0x08>;
			status = "disabled";

			glink_edge {
				qcom,glink-channels = "rpm_requests";
				qcom,rpm-channel-type = <0x0f>;
			};
		};

		qcom,rpm-glink {
			compatible = "qcom,rpm-glink";
			qcom,glink-edge = "rpm";
			rpm-channel-name = "rpm_requests";
			qcom,rpm-channel-type = <0x0f>;
			status = "disabled";
		};

		qcom,ipc_router {
			compatible = "qcom,ipc_router";
			qcom,node-id = <0x01>;
		};

		qcom,ipc_router_modem_xprt {
			compatible = "qcom,ipc_router_glink_xprt";
			qcom,ch-name = "IPCRTR";
			qcom,xprt-remote = "mpss";
			qcom,glink-xprt = "smem";
			qcom,xprt-linkid = <0x01>;
			qcom,xprt-version = <0x01>;
			qcom,fragmented-data;
		};

		qcom,ipc_router_adsp_xprt {
			compatible = "qcom,ipc_router_glink_xprt";
			qcom,ch-name = "IPCRTR";
			qcom,xprt-remote = "adsp";
			qcom,glink-xprt = "smem";
			qcom,xprt-linkid = <0x01>;
			qcom,xprt-version = <0x01>;
			qcom,fragmented-data;
			status = "disabled";
		};

		syscon@b111000 {
			compatible = "syscon";
			reg = <0xb111000 0x1000>;
			linux,phandle = <0x16>;
			phandle = <0x16>;
		};

		smp2p-wcss {
			compatible = "qcom,smp2p";
			qcom,smem = <0x1b3 0x1ac>;
			interrupt-parent = <0x01>;
			interrupts = <0x00 0x142 0x01>;
			qcom,ipc = <0x16 0x08 0x09>;
			qcom,local-pid = <0x00>;
			qcom,remote-pid = <0x01>;

			master-kernel {
				qcom,entry-name = "master-kernel";
				qcom,smp2p-feature-ssr-ack;
				#qcom,smem-state-cells = <0x01>;
				linux,phandle = <0x1c>;
				phandle = <0x1c>;
			};

			slave-kernel {
				qcom,entry-name = "slave-kernel";
				interrupt-controller;
				#interrupt-cells = <0x02>;
				linux,phandle = <0x1b>;
				phandle = <0x1b>;
			};
		};

		smp2p-adsp {
			compatible = "qcom,smp2p";
			qcom,smem = <0x1bb 0x1ad>;
			status = "disabled";
			interrupt-parent = <0x01>;
			interrupts = <0x00 0x1a 0x01>;
			qcom,ipc = <0x16 0x08 0x15>;
			qcom,local-pid = <0x00>;
			qcom,remote-pid = <0x02>;

			master-kernel {
				qcom,entry-name = "master-kernel";
				qcom,smp2p-feature-ssr-ack;
				#qcom,smem-state-cells = <0x01>;
				linux,phandle = <0x22>;
				phandle = <0x22>;
			};

			slave-kernel {
				qcom,entry-name = "slave-kernel";
				interrupt-controller;
				#interrupt-cells = <0x02>;
				linux,phandle = <0x21>;
				phandle = <0x21>;
			};
		};

		q6v5_wcss@CD00000 {
			compatible = "qca,q6v5-wcss-rproc-ipq60xx";
			firmware = "IPQ6018/q6_fw.mdt";
			reg = <0xcd00000 0x4040 0x194f000 0x10 0x1952000 0x10 0x4ab000 0x20 0x1818000 0x110 0x1859000 0x10 0x1945000 0x10>;
			reg-names = "wcss-base", "tcsr-q6-base", "tcsr-base", "mpm-base", "gcc-wcss-bcr-base", "gcc-wcss-misc-base", "tcsr-global";
			clocks = <0x03 0xce 0x03 0xcf 0x03 0xd0 0x03 0xd1 0x03 0xcb 0x03 0xcc 0x03 0xcd 0x03 0xd2 0x03 0xd4>;
			clock-names = "wcss_axi_m_clk", "sys_noc_wcss_ahb_clk", "q6_axim_clk", "q6ss_atbm_clk", "q6ss_pclkdbg_clk", "q6_tsctr_1to2_clk", "wcss_core_tbu_clk", "wcss_q6_tbu_clk", "gcc_q6_ahb_clk";
			qca,auto-restart;
			qca,extended-intc;
			qca,sec-reset-cmd = <0x18>;
			qca,secure;
			interrupts-extended = <0x01 0x00 0x145 0x01 0x1b 0x00 0x00 0x1b 0x01 0x00 0x1b 0x03 0x00>;
			interrupt-names = "wdog", "qcom,gpio-err-fatal", "qcom,gpio-err-ready", "qcom,gpio-stop-ack";
			qcom,smem-states = <0x1c 0x00 0x1c 0x01>;
			qcom,smem-state-names = "shutdown", "stop";
			memory-region = <0x1d 0x1e>;
			linux,phandle = <0x20>;
			phandle = <0x20>;
		};

		q6v5_m3 {
			compatible = "qca,q6v5-m3-rproc";
			firmware = "IPQ6018/m3_fw.mdt";
			qca,auto-restart;
			qcom,restart-group = <0x1f 0x20>;
			linux,phandle = <0x1f>;
			phandle = <0x1f>;
		};

		q6v6_adsp@AB00000 {
			status = "disabled";
			compatible = "qca,q6v6-adsp-rproc";
			firmware = "IPQ6018/adsp.mdt";
			reg = <0xab00000 0x4040 0x181f000 0x04 0xa000000 0x48000 0x1954010 0x20>;
			reg-names = "adsp-base", "gcc-adsp-bcr-base", "adsp-cc-base", "tcsr-base";
			qca,extended-intc;
			qca,sec-reset-cmd = <0x18>;
			qca,secure;
			interrupts-extended = <0x01 0x00 0x1e 0x01 0x21 0x00 0x00 0x21 0x01 0x00 0x21 0x03 0x00>;
			interrupt-names = "wdog", "qcom,gpio-err-fatal", "qcom,gpio-err-ready", "qcom,gpio-stop-ack";
			qcom,smem-states = <0x22 0x00 0x22 0x01>;
			qcom,smem-state-names = "shutdown", "stop";
			clocks = <0x03 0xf5 0x03 0xf6 0x03 0xe4 0x03 0xe5 0x03 0xe6 0x03 0xe7 0x03 0xe8 0x03 0xe9 0x03 0xea 0x03 0xeb 0x03 0xef>;
			clock-names = "mem_noc_lpass_clk", "snoc_lpass_cfg_clk", "lpass_core_axim_clk", "lpass_snoc_cfg_clk", "lpass_q6_axim_clk", "lpass_q6_atbm_at_clk", "lpass_q6_pclkdbg_clk", "lpass_q6ss_tsctr_1to2_clk", "lpass_q6ss_trig_clk", "lpass_tbu_clk", "pcnoc_lpass_clk";
		};

		qcom,adsprpc_loader {
			compatible = "qti,adsprpc-loader";
			status = "disabled";
		};

		qcom,glink-ssr-modem {
			compatible = "qcom,glink_ssr";
			label = "q6v5-wcss";
			qcom,edge = "mpss";
			qca,no-notify-edges;
			qcom,xprt = "smem";
		};

		qcom,glink-ssr-adsp {
			compatible = "qcom,glink_ssr";
			label = "q6v6-adsp";
			qcom,edge = "adsp";
			qcom,notify-edges = <0x23>;
			qcom,xprt = "smem";
			status = "disabled";
		};

		qcom,glink-ssr-rpm {
			compatible = "qcom,glink_ssr";
			label = "rpm";
			qcom,edge = "rpm";
			qcom,no-notify-edges;
			qcom,xprt = "smem";
			linux,phandle = <0x23>;
			phandle = <0x23>;
		};

		dma@7984000 {
			compatible = "qcom,bam-v1.7.0";
			reg = <0x7984000 0x1a000>;
			interrupts = <0x00 0x92 0x00>;
			clocks = <0x03 0x89>;
			clock-names = "bam_clk";
			#dma-cells = <0x01>;
			qcom,ee = <0x00>;
			status = "ok";
			linux,phandle = <0x09>;
			phandle = <0x09>;
		};

		qcom,sps {
			compatible = "qcom,msm_sps_4k";
			qcom,pipe-attr-ee;
		};

		qpic-nand@79b0000 {
			compatible = "qcom,ebi2-nandc-bam-v1.5.0";
			reg = <0x79b0000 0x10000>;
			#address-cells = <0x01>;
			#size-cells = <0x00>;
			clocks = <0x03 0x8a 0x03 0x89>;
			clock-names = "core", "aon";
			param-read-addr-cycle = <0x01>;
			dmas = <0x09 0x00 0x09 0x01 0x09 0x02>;
			dma-names = "tx", "rx", "cmd";
			status = "disabled";

			nandcs@0 {
				compatible = "qcom,nandcs";
				reg = <0x00>;
				#address-cells = <0x01>;
				#size-cells = <0x01>;
				nand-ecc-strength = <0x04>;
				nand-ecc-step-size = <0x200>;
				nand-bus-width = <0x08>;
			};
		};

		sdcc1ice@7808000 {
			compatible = "qcom,ice";
			reg = <0x7808000 0x2000>;
			interrupts = <0x00 0x138 0x00>;
			qcom,msm-bus,vectors-KBps = <0x4e 0x200 0x00 0x00 0x4e 0x200 0x3e8 0x00>;
			qcom,bus-vector-names = "MIN", "MAX";
			qcom,instance-type = "sdcc";
			linux,phandle = <0x24>;
			phandle = <0x24>;
		};

		sdhci@7804000 {
			compatible = "qcom,sdhci-msm-v5";
			reg = <0x7804000 0x1000 0x7805000 0x1000>;
			reg-names = "hc_mem", "cmdq_mem";
			interrupts = <0x00 0x7b 0x00 0x00 0x8a 0x00>;
			interrupt-names = "hc_irq", "pwr_irq";
			qcom,bus-width = <0x08>;
			sdhc-msm-crypto = <0x24>;
			qcom,max_clk = <0xb71b000>;
			qcom,dedicated-io = <0x01>;
			qcom,vdd-voltage-level = <0x2c4020 0x2c4020>;
			qcom,vdd-current-level = <0xc8 0x8b290>;
			qcom,vdd-io-lpm-sup;
			qcom,vdd-io-voltage-level = <0x1b7740 0x1b7740>;
			qcom,vdd-io-current-level = <0xc8 0x4f588>;
			qcom,vdd-io-always-on;
			qcom,cpu-dma-latency-us = <0x2bd>;
			qcom,msm-bus,name = "sdhc1";
			qcom,msm-bus,num-cases = <0x09>;
			qcom,msm-bus,num-paths = <0x01>;
			qcom,msm-bus,vectors-KBps = <0x4e 0x200 0x00 0x00 0x4e 0x200 0x416 0xc80 0x4e 0x200 0xcc3e 0x27100 0x4e 0x200 0xff50 0x30d40 0x4e 0x200 0x1fe9e 0x61a80 0x4e 0x200 0x3fd3e 0xc3500 0x4e 0x200 0x3fd3e 0xc3500 0x4e 0x200 0x3fd3e 0xc3500 0x4e 0x200 0x146cc2 0x3e8000>;
			qcom,bus-bw-vectors-bps = <0x00 0x61a80 0x1312d00 0x17d7840 0x2faf080 0x5f5e100 0xbebc200 0x17d78400 0xffffffff>;
			clocks = <0x03 0x8b 0x03 0x8c 0x03 0xc3>;
			clock-names = "iface_clk", "core_clk", "ice_core_clk";
			qcom,ice-clk-rates = <0x9896800 0x12646790>;
			qcom,large-address-bus;
			qcom,disable-aggressive-pm;
			qcom,clk-rates = <0x61a80 0x17d7840 0x2faf080 0x5f5e100 0xb71b000>;
			qcom,bus-speed-mode = "HS200_1p8v", "DDR_1p8v";
			qcom,nonremovable;
			status = "ok";
		};

		sdhci_sd@7804000 {
			compatible = "qcom,sdhci-msm-v5";
			reg = <0x7804000 0x1000>;
			reg-names = "hc_mem";
			interrupts = <0x00 0x7b 0x00 0x00 0x8a 0x00>;
			interrupt-names = "hc_irq", "pwr_irq";
			qcom,max_clk = <0xb71b000>;
			qcom,bus-width = <0x04>;
			qcom,dedicated-io = <0x01>;
			qcom,vdd-voltage-level = <0x2d0370 0x2d0370>;
			qcom,vdd-current-level = <0x3a98 0x61a80>;
			qcom,vdd-io-lpm-sup;
			qcom,vdd-io-voltage-level = <0x1b7740 0x2d0370>;
			qcom,vdd-io-current-level = <0xc8 0x55f0>;
			qcom,vdd-io-always-on;
			qcom,cpu-dma-latency-us = <0x2bd>;
			qcom,msm-bus,name = "sdhc2";
			qcom,msm-bus,num-cases = <0x08>;
			qcom,msm-bus,num-paths = <0x01>;
			qcom,msm-bus,vectors-KBps = <0x51 0x200 0x00 0x00 0x51 0x200 0x416 0xc80 0x51 0x200 0xcc3e 0x27100 0x51 0x200 0xff50 0x30d40 0x51 0x200 0x1fe9e 0x61a80 0x51 0x200 0x3fd3e 0xc3500 0x51 0x200 0x3fd3e 0xc3500 0x51 0x200 0x146cc2 0x3e8000>;
			qcom,bus-bw-vectors-bps = <0x00 0x61a80 0x1312d00 0x17d7840 0x2faf080 0x5f5e100 0xbebc200 0xffffffff>;
			clocks = <0x03 0x8b 0x03 0x8c>;
			clock-names = "iface_clk", "core_clk";
			qcom,large-address-bus;
			qcom,disable-aggressive-pm;
			qcom,clk-rates = <0x61a80 0x17d7840 0x2faf080 0x5f5e100 0xb71b000>;
			qcom,bus-speed-mode = "HS200_1p8v", "DDR_1p8v";
			status = "disabled";
		};

		edma@3ab00000 {
			compatible = "qcom,edma";
			reg = <0x3ab00000 0xabe00>;
			reg-names = "edma-reg-base";
			qcom,txdesc-ring-start = <0x17>;
			qcom,txdesc-rings = <0x01>;
			qcom,txcmpl-ring-start = <0x17>;
			qcom,txcmpl-rings = <0x01>;
			qcom,rxfill-ring-start = <0x07>;
			qcom,rxfill-rings = <0x01>;
			qcom,rxdesc-ring-start = <0x0f>;
			qcom,rxdesc-rings = <0x01>;
			interrupts = <0x00 0x17a 0x04 0x00 0x162 0x04 0x00 0x15a 0x04 0x00 0x17b 0x04>;
			resets = <0x03 0x6d>;
			reset-names = "edma_rst";
		};

		nss-common {
			compatible = "qcom,nss-common";
			reg = <0x1868010 0x1000 0x40000000 0x1000>;
			reg-names = "nss-misc-reset", "nss-misc-reset-flag";
		};

		nss@40000000 {
			compatible = "qcom,nss";
			interrupts = <0x00 0x192 0x01 0x00 0x191 0x01 0x00 0x190 0x01 0x00 0x18f 0x01 0x00 0x18e 0x01 0x00 0x18d 0x01 0x00 0x18c 0x01 0x00 0x18b 0x01 0x00 0x18a 0x01 0x00 0x189 0x01>;
			reg = <0x39000000 0x1000 0xb111000 0x1000>;
			reg-names = "nphys", "qgic-phys";
			clocks = <0x03 0x64 0x03 0x72 0x03 0x61 0x03 0x5f 0x03 0x78 0x03 0xae 0x03 0x79 0x03 0xf4 0x03 0x5e 0x03 0x5d 0x03 0x74 0x03 0x73 0x03 0x7a 0x03 0x82 0x03 0x80 0x03 0x81 0x03 0xaf 0x03 0xf0 0x03 0xf2>;
			clock-names = "nss-noc-clk", "nss-ptp-ref-clk", "nss-csr-clk", "nss-cfg-clk", "nss-nssnoc-qosgen-ref-clk", "nss-nssnoc-snoc-clk", "nss-nssnoc-timeout-ref-clk", "nss-mem-noc-ubi32-clk", "nss-ce-axi-clk", "nss-ce-apb-clk", "nss-nssnoc-ce-axi-clk", "nss-nssnoc-ce-apb-clk", "nss-nssnoc-ahb-clk", "nss-core-clk", "nss-ahb-clk", "nss-axi-clk", "nss-nc-axi-clk", "nss-utcm-clk", "nss-snoc-nssnoc-clk";
			qcom,id = <0x00>;
			qcom,num-queue = <0x04>;
			qcom,num-irq = <0x0a>;
			qcom,num-pri = <0x04>;
			qcom,load-addr = <0x40000000>;
			qcom,low-frequency = "\v(r";
			qcom,mid-frequency = <0x2ca1c800>;
			qcom,max-frequency = <0x59439000>;
			qcom,bridge-enabled;
			qcom,ipv4-enabled;
			qcom,ipv4-reasm-enabled;
			qcom,ipv6-enabled;
			qcom,ipv6-reasm-enabled;
			qcom,wlanredirect-enabled;
			qcom,tun6rd-enabled;
			qcom,l2tpv2-enabled;
			qcom,gre-enabled;
			qcom,gre-redir-enabled;
			qcom,gre-redir-mark-enabled;
			qcom,map-t-enabled;
			qcom,portid-enabled;
			qcom,ppe-enabled;
			qcom,pppoe-enabled;
			qcom,pptp-enabled;
			qcom,tunipip6-enabled;
			qcom,shaping-enabled;
			qcom,wlan-dataplane-offload-enabled;
			qcom,vlan-enabled;
			qcom,capwap-enabled;
			qcom,dtls-enabled;
			qcom,tls-enabled;
			qcom,crypto-enabled;
			qcom,ipsec-enabled;
			qcom,qvpn-enabled;
			qcom,pvxlan-enabled;
			qcom,clmap-enabled;
			qcom,vxlan-enabled;
			qcom,match-enabled;
			qcom,mirror-enabled;
		};

		qcom,nss_crypto {
			compatible = "qcom,nss-crypto";
			#address-cells = <0x01>;
			#size-cells = <0x01>;
			qcom,max-contexts = <0x40>;
			qcom,max-context-size = <0x20>;
			ranges;
			status = "ok";

			eip197_node {
				compatible = "qcom,eip197";
				reg-names = "crypto_pbase";
				reg = <0x39800000 0x7ffff>;
				clocks = <0x03 0x60 0x03 0x75 0x03 0x5c>;
				clock-names = "crypto_clk", "crypto_nocclk", "crypto_ppeclk";
				clock-frequency = <0x00 0x11e1a300 0x00 0x11e1a300 0x00 0x11e1a300>;
				qcom,dma-mask = <0xff>;
				qcom,transform-enabled;
				qcom,aes128-cbc;
				qcom,aes192-cbc;
				qcom,aes256-cbc;
				qcom,aes128-ctr;
				qcom,aes192-ctr;
				qcom,aes256-ctr;
				qcom,aes128-ecb;
				qcom,aes192-ecb;
				qcom,aes256-ecb;
				qcom,3des-cbc;
				qcom,md5-hash;
				qcom,sha160-hash;
				qcom,sha224-hash;
				qcom,sha256-hash;
				qcom,sha384-hash;
				qcom,sha512-hash;
				qcom,md5-hmac;
				qcom,sha160-hmac;
				qcom,sha224-hmac;
				qcom,sha256-hmac;
				qcom,sha384-hmac;
				qcom,sha512-hmac;
				qcom,aes128-gcm-gmac;
				qcom,aes192-gcm-gmac;
				qcom,aes256-gcm-gmac;
				qcom,aes128-cbc-md5-hmac;
				qcom,aes128-cbc-sha160-hmac;
				qcom,aes192-cbc-md5-hmac;
				qcom,aes192-cbc-sha160-hmac;
				qcom,aes256-cbc-md5-hmac;
				qcom,aes256-cbc-sha160-hmac;
				qcom,aes128-ctr-sha160-hmac;
				qcom,aes192-ctr-sha160-hmac;
				qcom,aes256-ctr-sha160-hmac;
				qcom,aes128-ctr-md5-hmac;
				qcom,aes192-ctr-md5-hmac;
				qcom,aes256-ctr-md5-hmac;
				qcom,3des-cbc-md5-hmac;
				qcom,3des-cbc-sha160-hmac;
				qcom,aes128-cbc-sha256-hmac;
				qcom,aes192-cbc-sha256-hmac;
				qcom,aes256-cbc-sha256-hmac;
				qcom,aes128-ctr-sha256-hmac;
				qcom,aes192-ctr-sha256-hmac;
				qcom,aes256-ctr-sha256-hmac;
				qcom,3des-cbc-sha256-hmac;
				qcom,aes128-cbc-sha384-hmac;
				qcom,aes192-cbc-sha384-hmac;
				qcom,aes256-cbc-sha384-hmac;
				qcom,aes128-ctr-sha384-hmac;
				qcom,aes192-ctr-sha384-hmac;
				qcom,aes256-ctr-sha384-hmac;
				qcom,aes128-cbc-sha512-hmac;
				qcom,aes192-cbc-sha512-hmac;
				qcom,aes256-cbc-sha512-hmac;
				qcom,aes128-ctr-sha512-hmac;
				qcom,aes192-ctr-sha512-hmac;
				qcom,aes256-ctr-sha512-hmac;

				engine0 {
					reg_offset = <0x80000>;
					qcom,ifpp-enabled;
					qcom,ipue-enabled;
					qcom,ofpp-enabled;
					qcom,opue-enabled;
				};
			};
		};

		clock-controller@b188000 {
			compatible = "qcom,arm-cortex-acc";
			reg = <0xb188000 0x1000>;
			linux,phandle = <0x56>;
			phandle = <0x56>;
		};

		clock-controller@b198000 {
			compatible = "qcom,arm-cortex-acc";
			reg = <0xb198000 0x1000>;
			linux,phandle = <0x59>;
			phandle = <0x59>;
		};

		clock-controller@b1a8000 {
			compatible = "qcom,arm-cortex-acc";
			reg = <0xb1a8000 0x1000>;
			linux,phandle = <0x5a>;
			phandle = <0x5a>;
		};

		clock-controller@b1b8000 {
			compatible = "qcom,arm-cortex-acc";
			reg = <0xb1b8000 0x1000>;
			linux,phandle = <0x5b>;
			phandle = <0x5b>;
		};

		pinctrl@1000000 {
			compatible = "qcom,ipq6018-pinctrl";
			reg = <0x1000000 0x300000>;
			interrupts = <0x00 0xd0 0x00>;
			gpio-controller;
			#gpio-cells = <0x02>;
			interrupt-controller;
			#interrupt-cells = <0x02>;
			pinctrl-names = "default";
			pinctrl-0 = <0x25 0x26>;
			linux,phandle = <0x0e>;
			phandle = <0x0e>;

			uart_pins {
				linux,phandle = <0x06>;
				phandle = <0x06>;

				mux {
					pins = "gpio44", "gpio45";
					function = "blsp2_uart";
					drive-strength = <0x08>;
					bias-pull-down;
				};
			};

			uart_4_pins {
				linux,phandle = <0x07>;
				phandle = <0x07>;

				mux {
					pins = "gpio75", "gpio76";
					function = "blsp3_uart";
					drive-strength = <0x08>;
					bias-pull-down;
				};
			};

			spi_0_pins {
				linux,phandle = <0x13>;
				phandle = <0x13>;

				mux {
					pins = "gpio38", "gpio39", "gpio40", "gpio41";
					function = "blsp0_spi";
					drive-strength = <0x08>;
					bias-pull-down;
				};
			};

			spi_4_pins {
				linux,phandle = <0x14>;
				phandle = <0x14>;

				mux {
					pins = "gpio55", "gpio56", "gpio57", "gpio58";
					function = "blsp4_spi";
					drive-strength = <0x08>;
					bias-pull-down;
				};
			};

			sd_pins {

				mux {
					pins = "gpio62";
					function = "sd_card";
					drive-strength = <0x08>;
					bias-pull-up;
				};
			};

			extcon_usb_pins {
				linux,phandle = <0x0d>;
				phandle = <0x0d>;

				mux {
					pins = "gpio26";
					function = "gpio";
					drive-strength = <0x02>;
					bias-pull-down;
				};
			};

			button_pins {
				linux,phandle = <0x54>;
				phandle = <0x54>;

				wps_button {
					pins = "gpio9";
					function = "gpio";
					drive-strength = <0x08>;
					bias-pull-up;
				};

				reset_button {
					pins = "gpio19";
					function = "gpio";
					drive-strength = <0x08>;
					bias-pull-up;
				};
			};

			mdio_pinmux {
				linux,phandle = <0x28>;
				phandle = <0x28>;

				mux_0 {
					pins = "gpio64";
					function = "mdc";
					drive-strength = <0x08>;
					bias-pull-up;
				};

				mux_1 {
					pins = "gpio65";
					function = "mdio";
					drive-strength = <0x08>;
					bias-pull-up;
				};

				mux_3 {
					pins = "gpio77";
					function = "gpio";
					bias-pull-up;
				};
			};

			hsuart_pins {
				linux,phandle = <0x04>;
				phandle = <0x04>;

				mux {
					pins = "gpio71", "gpio72", "gpio69", "gpio70";
					function = "blsp1_uart";
					drive-strength = <0x08>;
					bias-disable;
				};
			};

			led_pinmux {
				linux,phandle = <0x25>;
				phandle = <0x25>;

				gps_reset_pin {
					pins = "gpio22";
					function = "gpio";
					drive-strength = <0x08>;
					bias-pull-up;
					output-high;
				};

				bt_mcuboot {
					pins = "gpio15";
					function = "gpio";
					drive-strength = <0x08>;
					bias-pull-up;
					output-high;
				};

				bt_reset_pin {
					pins = "gpio43";
					function = "gpio";
					drive-strength = <0x08>;
					bias-pull-up;
					output-low;
				};

				usb_en_pin {
					pins = "gpio67";
					function = "gpio";
					drive-strength = <0x08>;
					output-high;
				};
			};

			generic-input-pinmux {
				linux,phandle = <0x26>;
				phandle = <0x26>;

				poe_detect {
					pins = "gpio16", "gpio18", "gpio35", "gpio37", "gpio68";
					function = "gpio";
					bias-disable;
				};

				usb_current_over_limit {
					pins = "gpio66";
					function = "gpio";
					bias-disable;
				};
			};

			leds_pins {
				linux,phandle = <0x55>;
				phandle = <0x55>;

				lan1_g_led {
					pins = "gpio0";
					function = "gpio";
					drive-strength = <0x08>;
					bias-pull-down;
				};

				lan1_r_led {
					pins = "gpio1";
					function = "gpio";
					drive-strength = <0x08>;
					bias-pull-down;
				};

				lan0_g_led {
					pins = "gpio4";
					function = "gpio";
					drive-strength = <0x08>;
					bias-pull-down;
				};

				lan0_r_led {
					pins = "gpio5";
					function = "gpio";
					drive-strength = <0x08>;
					bias-pull-down;
				};

				6g_g_led {
					pins = "gpio6";
					function = "gpio";
					drive-strength = <0x08>;
					bias-pull-down;
				};

				6g_r_led {
					pins = "gpio7";
					function = "gpio";
					drive-strength = <0x08>;
					bias-pull-down;
				};

				5g_g_led {
					pins = "gpio8";
					function = "gpio";
					drive-strength = <0x08>;
					bias-pull-down;
				};

				5g_r_led {
					pins = "gpio9";
					function = "gpio";
					drive-strength = <0x08>;
					bias-pull-down;
				};

				2g_g_led {
					pins = "gpio11";
					function = "gpio";
					drive-strength = <0x08>;
					bias-pull-down;
				};

				2g_r_led {
					pins = "gpio12";
					function = "gpio";
					drive-strength = <0x08>;
					bias-pull-down;
				};

				pwr_g_led {
					pins = "gpio13";
					function = "gpio";
					drive-strength = <0x08>;
					bias-pull-down;
				};

				pwr_r_led {
					pins = "gpio14";
					function = "gpio";
					drive-strength = <0x08>;
					bias-pull-up;
				};
			};
		};

		watchdog@b017000 {
			compatible = "qcom,kpss-wdt-ipq6018";
			reg = <0xb017000 0x1000>;
			reg-names = "kpss_wdt";
			interrupt-names = "bark_irq";
			interrupts = <0x00 0x03 0x00>;
			clocks = <0x27>;
			timeout-sec = <0x1e>;
			wdt-max-timeout = <0x20>;
		};

		mdio@90000 {
			#address-cells = <0x01>;
			#size-cells = <0x01>;
			compatible = "qcom,qca-mdio", "qcom,ipq40xx-mdio";
			reg = <0x90000 0x64>;
			status = "ok";
			pinctrl-0 = <0x28>;
			pinctrl-names = "default";
			phy-reset-gpio = <0x0e 0x4d 0x00>;
			linux,phandle = <0x53>;
			phandle = <0x53>;

			ethernet-phy@0 {
				reg = <0x10>;
			};

			ethernet-phy@1 {
				reg = <0x14>;
			};
		};

		qcom_q6v5_wcss@CD00000 {
			compatible = "qcom,ipq60xx-wcss-pil";
			firmware = "IPQ6018/q6_fw.mdt";
			m3_firmware = "IPQ6018/m3_fw.mdt";
			reg = <0xcd00000 0x4040 0x4ab000 0x20>;
			reg-names = "qdsp6", "rmb";
			qca,auto-restart;
			qca,extended-intc;
			qcom,wcss-aon-reset-quirk;
			interrupts-extended = <0x01 0x00 0x145 0x01 0x1b 0x00 0x00 0x1b 0x01 0x00 0x1b 0x02 0x00 0x1b 0x03 0x00>;
			interrupt-names = "wdog", "fatal", "ready", "handover", "stop-ack";
			resets = <0x03 0x7f 0x03 0x16 0x03 0x17>;
			reset-names = "wcss_aon_reset", "wcss_reset", "wcss_q6_reset";
			qcom,halt-regs = <0x29 0xa000 0xd000 0x00>;
			qcom,smem-states = <0x1c 0x00 0x1c 0x01>;
			qcom,smem-state-names = "shutdown", "stop";
			memory-region = <0x1d 0x1e>;
			linux,phandle = <0x2c>;
			phandle = <0x2c>;

			glink-edge {
				interrupts = <0x00 0x141 0x01>;
				qcom,remote-pid = <0x01>;
				mboxes = <0x2a 0x08>;
				global_timer = "", "JP";

				rpm_requests {
					qcom,glink-channels = "IPCRTR";
				};
			};
		};

		qcom_q6v6_adsp@AB00000 {
			status = "disabled";
			compatible = "qcom,ipq6018-adsp-pil";
			interrupts-extended = <0x01 0x00 0x1e 0x01 0x21 0x00 0x00 0x21 0x01 0x00 0x21 0x02 0x00 0x21 0x03 0x00>;
			interrupt-names = "wdog", "fatal", "ready", "handover", "stop-ack";
			qcom,smem-states = <0x22 0x00 0x22 0x01>;
			qcom,smem-state-names = "shutdown", "stop";

			glink-edge {
				interrupts = <0x00 0x18 0x01>;
				qcom,remote-pid = <0x02>;
				mboxes = <0x2b 0x08>;

				rpm_requests {
					qcom,glink-channels = "IPCRTR";
				};

				qcom,msm_fastrpc_rpmsg {
					compatible = "qcom,msm-fastrpc-rpmsg";
					qcom,glink-channels = "fastrpcglink-apps-dsp";
					qcom,intents = <0x64 0x40>;
				};
			};
		};

		ess-switch@3a000000 {
			compatible = "qcom,ess-switch-ipq60xx";
			reg = <0x3a000000 0x1000000>;
			switch_access_mode = "local bus";
			clocks = <0x03 0xb7 0x03 0xb8 0x03 0x8d 0x03 0x98 0x03 0x99 0x03 0x9c 0x03 0x7b 0x03 0x7c 0x03 0x7d 0x03 0x7e 0x03 0x7f 0x03 0x70 0x03 0x6f 0x03 0x77 0x03 0x76 0x03 0x63 0x03 0x62 0x03 0x71 0x03 0x5b 0x03 0x64 0x03 0xae 0x03 0x60 0x03 0x72 0x03 0x65 0x03 0x66 0x03 0x67 0x03 0x68 0x03 0x69 0x03 0x6a 0x03 0x6b 0x03 0x6c 0x03 0x6d 0x03 0x6e 0x03 0x8e 0x03 0x8f 0x03 0x90 0x03 0x91 0x03 0x92 0x03 0x93 0x03 0x94 0x03 0x95 0x03 0x96 0x03 0x97 0x03 0x9a 0x03 0x9b 0x03 0x0c 0x03 0x0d 0x03 0xf2>;
			clock-names = "cmn_ahb_clk", "cmn_sys_clk", "uniphy0_ahb_clk", "uniphy0_sys_clk", "uniphy1_ahb_clk", "uniphy1_sys_clk", "port1_mac_clk", "port2_mac_clk", "port3_mac_clk", "port4_mac_clk", "port5_mac_clk", "nss_ppe_clk", "nss_ppe_cfg_clk", "nssnoc_ppe_clk", "nssnoc_ppe_cfg_clk", "nss_edma_clk", "nss_edma_cfg_clk", "nss_ppe_ipe_clk", "gcc_mdio_ahb_clk", "gcc_nss_noc_clk", "gcc_nssnoc_snoc_clk", "gcc_nss_crypto_clk", "gcc_nss_ptp_ref_clk", "nss_port1_rx_clk", "nss_port1_tx_clk", "nss_port2_rx_clk", "nss_port2_tx_clk", "nss_port3_rx_clk", "nss_port3_tx_clk", "nss_port4_rx_clk", "nss_port4_tx_clk", "nss_port5_rx_clk", "nss_port5_tx_clk", "uniphy0_port1_rx_clk", "uniphy0_port1_tx_clk", "uniphy0_port2_rx_clk", "uniphy0_port2_tx_clk", "uniphy0_port3_rx_clk", "uniphy0_port3_tx_clk", "uniphy0_port4_rx_clk", "uniphy0_port4_tx_clk", "uniphy0_port5_rx_clk", "uniphy0_port5_tx_clk", "uniphy1_port5_rx_clk", "uniphy1_port5_tx_clk", "nss_port5_rx_clk_src", "nss_port5_tx_clk_src", "gcc_snoc_nssnoc_clk";
			resets = <0x03 0x68 0x03 0x69 0x03 0x6a 0x03 0x6b 0x03 0x6c 0x03 0x70 0x03 0x71 0x03 0x72 0x03 0x73 0x03 0x74 0x03 0x75 0x03 0x76 0x03 0x77 0x03 0x78 0x03 0x79 0x03 0x7a 0x03 0x7b>;
			reset-names = "ppe_rst", "uniphy0_soft_rst", "uniphy0_xpcs_rst", "uniphy1_soft_rst", "uniphy1_xpcs_rst", "nss_port1_rst", "nss_port2_rst", "nss_port3_rst", "nss_port4_rst", "nss_port5_rst", "uniphy0_port1_dis", "uniphy0_port2_dis", "uniphy0_port3_dis", "uniphy0_port4_dis", "uniphy0_port5_dis", "uniphy0_port_4_5_rst", "uniphy0_port_4_rst";
			switch_cpu_bmp = <0x01>;
			switch_lan_bmp = <0x10>;
			switch_wan_bmp = <0x20>;
			switch_inner_bmp = <0xc0>;
			switch_mac_mode = <0x0f>;
			switch_mac_mode1 = <0x0f>;
			switch_mac_mode2 = <0xff>;
			bm_tick_mode = <0x00>;
			tm_tick_mode = <0x00>;

			port_scheduler_resource {

				port@0 {
					port_id = <0x00>;
					ucast_queue = <0x00 0x8f>;
					mcast_queue = <0x100 0x10f>;
					l0sp = <0x00 0x23>;
					l0cdrr = <0x00 0x2f>;
					l0edrr = <0x00 0x2f>;
					l1cdrr = <0x00 0x07>;
					l1edrr = <0x00 0x07>;
				};

				port@1 {
					port_id = <0x01>;
					ucast_queue = <0x90 0x9f>;
					mcast_queue = <0x110 0x113>;
					l0sp = <0x24 0x27>;
					l0cdrr = <0x30 0x3f>;
					l0edrr = <0x30 0x3f>;
					l1cdrr = <0x08 0x0b>;
					l1edrr = <0x08 0x0b>;
				};

				port@2 {
					port_id = <0x02>;
					ucast_queue = <0xa0 0xaf>;
					mcast_queue = <0x114 0x117>;
					l0sp = <0x28 0x2b>;
					l0cdrr = <0x40 0x4f>;
					l0edrr = <0x40 0x4f>;
					l1cdrr = <0x0c 0x0f>;
					l1edrr = <0x0c 0x0f>;
				};

				port@3 {
					port_id = <0x03>;
					ucast_queue = <0xb0 0xbf>;
					mcast_queue = <0x118 0x11b>;
					l0sp = <0x2c 0x2f>;
					l0cdrr = <0x50 0x5f>;
					l0edrr = <0x50 0x5f>;
					l1cdrr = <0x10 0x13>;
					l1edrr = <0x10 0x13>;
				};

				port@4 {
					port_id = <0x04>;
					ucast_queue = <0xc0 0xcf>;
					mcast_queue = <0x11c 0x11f>;
					l0sp = <0x30 0x33>;
					l0cdrr = <0x60 0x6f>;
					l0edrr = <0x60 0x6f>;
					l1cdrr = <0x14 0x17>;
					l1edrr = <0x14 0x17>;
				};

				port@5 {
					port_id = <0x05>;
					ucast_queue = <0xd0 0xdf>;
					mcast_queue = <0x120 0x123>;
					l0sp = <0x34 0x37>;
					l0cdrr = <0x70 0x7f>;
					l0edrr = <0x70 0x7f>;
					l1cdrr = <0x18 0x1b>;
					l1edrr = <0x18 0x1b>;
				};

				port@6 {
					port_id = <0x06>;
					ucast_queue = <0xe0 0xef>;
					mcast_queue = <0x124 0x127>;
					l0sp = <0x38 0x3b>;
					l0cdrr = <0x80 0x8f>;
					l0edrr = <0x80 0x8f>;
					l1cdrr = <0x1c 0x1f>;
					l1edrr = <0x1c 0x1f>;
				};

				port@7 {
					port_id = <0x07>;
					ucast_queue = <0xf0 0xff>;
					mcast_queue = <0x128 0x12b>;
					l0sp = <0x3c 0x3f>;
					l0cdrr = <0x90 0x9f>;
					l0edrr = <0x90 0x9f>;
					l1cdrr = <0x20 0x23>;
					l1edrr = <0x20 0x23>;
				};
			};

			port_scheduler_config {

				port@0 {
					port_id = <0x00>;

					l1scheduler {

						group@0 {
							sp = <0x00 0x01>;
							cfg = <0x00 0x00 0x00 0x00>;
						};
					};

					l0scheduler {

						group@0 {
							ucast_queue = <0x00 0x04 0x08>;
							mcast_queue = <0x100 0x104>;
							cfg = <0x00 0x00 0x00 0x00 0x00>;
						};

						group@1 {
							ucast_queue = <0x01 0x05 0x09>;
							mcast_queue = <0x101 0x105>;
							cfg = <0x00 0x01 0x01 0x01 0x01>;
						};

						group@2 {
							ucast_queue = <0x02 0x06 0x0a>;
							mcast_queue = <0x102 0x106>;
							cfg = <0x00 0x02 0x02 0x02 0x02>;
						};

						group@3 {
							ucast_queue = <0x03 0x07 0x0b>;
							mcast_queue = <0x103 0x107>;
							cfg = <0x00 0x03 0x03 0x03 0x03>;
						};
					};
				};

				port@1 {
					port_id = <0x01>;

					l1scheduler {

						group@0 {
							sp = <0x24>;
							cfg = <0x00 0x08 0x00 0x08>;
						};

						group@1 {
							sp = <0x25>;
							cfg = <0x01 0x09 0x01 0x09>;
						};
					};

					l0scheduler {

						group@0 {
							ucast_queue = <0x90>;
							ucast_loop_pri = <0x10>;
							mcast_queue = <0x110>;
							mcast_loop_pri = <0x04>;
							cfg = <0x24 0x00 0x30 0x00 0x30>;
						};
					};
				};

				port@2 {
					port_id = <0x02>;

					l1scheduler {

						group@0 {
							sp = <0x28>;
							cfg = <0x00 0x0c 0x00 0x0c>;
						};

						group@1 {
							sp = <0x29>;
							cfg = <0x01 0x0d 0x01 0x0d>;
						};
					};

					l0scheduler {

						group@0 {
							ucast_queue = <0xa0>;
							ucast_loop_pri = <0x10>;
							mcast_queue = <0x114>;
							mcast_loop_pri = <0x04>;
							cfg = <0x28 0x00 0x40 0x00 0x40>;
						};
					};
				};

				port@3 {
					port_id = <0x03>;

					l1scheduler {

						group@0 {
							sp = <0x2c>;
							cfg = <0x00 0x10 0x00 0x10>;
						};

						group@1 {
							sp = <0x2d>;
							cfg = <0x01 0x11 0x01 0x11>;
						};
					};

					l0scheduler {

						group@0 {
							ucast_queue = <0xb0>;
							ucast_loop_pri = <0x10>;
							mcast_queue = <0x118>;
							mcast_loop_pri = <0x04>;
							cfg = <0x2c 0x00 0x50 0x00 0x50>;
						};
					};
				};

				port@4 {
					port_id = <0x04>;

					l1scheduler {

						group@0 {
							sp = <0x30>;
							cfg = <0x00 0x14 0x00 0x14>;
						};

						group@1 {
							sp = <0x31>;
							cfg = <0x01 0x15 0x01 0x15>;
						};
					};

					l0scheduler {

						group@0 {
							ucast_queue = <0xc0>;
							ucast_loop_pri = <0x10>;
							mcast_queue = <0x11c>;
							mcast_loop_pri = <0x04>;
							cfg = <0x30 0x00 0x60 0x00 0x60>;
						};
					};
				};

				port@5 {
					port_id = <0x05>;

					l1scheduler {

						group@0 {
							sp = <0x34>;
							cfg = <0x00 0x18 0x00 0x18>;
						};

						group@1 {
							sp = <0x35>;
							cfg = <0x01 0x19 0x01 0x19>;
						};
					};

					l0scheduler {

						group@0 {
							ucast_queue = <0xd0>;
							ucast_loop_pri = <0x10>;
							mcast_queue = <0x120>;
							mcast_loop_pri = <0x04>;
							cfg = <0x34 0x00 0x70 0x00 0x70>;
						};
					};
				};

				port@6 {
					port_id = <0x06>;

					l1scheduler {

						group@0 {
							sp = <0x38>;
							cfg = <0x00 0x1c 0x00 0x1c>;
						};

						group@1 {
							sp = <0x39>;
							cfg = <0x01 0x1d 0x01 0x1d>;
						};
					};

					l0scheduler {

						group@0 {
							ucast_queue = <0xe0>;
							ucast_loop_pri = <0x10>;
							mcast_queue = <0x124>;
							mcast_loop_pri = <0x04>;
							cfg = <0x38 0x00 0x80 0x00 0x80>;
						};
					};
				};

				port@7 {
					port_id = <0x07>;

					l1scheduler {

						group@0 {
							sp = <0x3c>;
							cfg = <0x00 0x20 0x00 0x20>;
						};

						group@1 {
							sp = <0x3d>;
							cfg = <0x01 0x21 0x01 0x21>;
						};
					};

					l0scheduler {

						group@0 {
							ucast_queue = <0xf0>;
							ucast_loop_pri = <0x10>;
							mcast_queue = <0x128>;
							cfg = <0x3c 0x00 0x90 0x00 0x90>;
						};
					};
				};
			};

			qcom,port_phyinfo {

				port@4 {
					port_id = <0x04>;
					phy_address = <0x10>;
					port_mac_sel = "QGMAC_PORT";
				};

				port@5 {
					port_id = <0x05>;
					phy_address = <0x14>;
					port_mac_sel = "QGMAC_PORT";
				};
			};
		};

		ess-uniphy@7a00000 {
			compatible = "qcom,ess-uniphy";
			reg = <0x7a00000 0x30000>;
			uniphy_access_mode = "local bus";
		};

		wifi@c000000 {
			compatible = "qcom,cnss-qca6018", "qcom,ipq6018-wifi";
			reg = <0xc000000 0x1000000>;
			qcom,hw-mode-id = <0x01>;
			qcom,tgt-mem-mode = <0x00>;
			qcom,bdf-addr = <0x4abc0000 0x4abc0000 0x4abc0000 0x00 0x00>;
			qcom,caldb-addr = <0x4b500000 0x4b500000 0x4b500000 0x00 0x00>;
			qcom,caldb-size = <0x480000>;
			qcom,rproc = <0x2c>;
			interrupts = <0x00 0x140 0x01 0x00 0x13f 0x01 0x00 0x13e 0x01 0x00 0x13c 0x01 0x00 0x13b 0x01 0x00 0x13a 0x01 0x00 0x137 0x01 0x00 0x136 0x01 0x00 0x19b 0x01 0x00 0x19a 0x01 0x00 0x28 0x01 0x00 0x27 0x01 0x00 0x12e 0x01 0x00 0x12d 0x01 0x00 0x25 0x01 0x00 0x24 0x01 0x00 0x128 0x01 0x00 0x127 0x01 0x00 0x126 0x01 0x00 0x125 0x01 0x00 0x124 0x01 0x00 0x123 0x01 0x00 0x122 0x01 0x00 0x121 0x01 0x00 0x120 0x01 0x00 0xef 0x01 0x00 0xec 0x01 0x00 0xeb 0x01 0x00 0xea 0x01 0x00 0xe9 0x01 0x00 0xe8 0x01 0x00 0xe7 0x01 0x00 0xe6 0x01 0x00 0xe5 0x01 0x00 0xe4 0x01 0x00 0xe0 0x01 0x00 0xdf 0x01 0x00 0xcb 0x01 0x00 0xb7 0x01 0x00 0xb4 0x01 0x00 0xb3 0x01 0x00 0xb2 0x01 0x00 0xb1 0x01 0x00 0xb0 0x01 0x00 0xa3 0x01 0x00 0xa2 0x01 0x00 0xa0 0x01 0x00 0x9f 0x01 0x00 0x9e 0x01 0x00 0x9d 0x01 0x00 0x9c 0x01>;
			interrupt-names = "misc-pulse1", "misc-latch", "sw-exception", "ce0", "ce1", "ce2", "ce3", "ce4", "ce5", "ce6", "ce7", "ce8", "ce9", "ce10", "ce11", "host2wbm-desc-feed", "host2reo-re-injection", "host2reo-command", "host2rxdma-monitor-ring3", "host2rxdma-monitor-ring2", "host2rxdma-monitor-ring1", "reo2ost-exception", "wbm2host-rx-release", "reo2host-status", "reo2host-destination-ring4", "reo2host-destination-ring3", "reo2host-destination-ring2", "reo2host-destination-ring1", "rxdma2host-monitor-destination-mac3", "rxdma2host-monitor-destination-mac2", "rxdma2host-monitor-destination-mac1", "ppdu-end-interrupts-mac3", "ppdu-end-interrupts-mac2", "ppdu-end-interrupts-mac1", "rxdma2host-monitor-status-ring-mac3", "rxdma2host-monitor-status-ring-mac2", "rxdma2host-monitor-status-ring-mac1", "host2rxdma-host-buf-ring-mac3", "host2rxdma-host-buf-ring-mac2", "host2rxdma-host-buf-ring-mac1", "rxdma2host-destination-ring-mac3", "rxdma2host-destination-ring-mac2", "rxdma2host-destination-ring-mac1", "host2tcl-input-ring4", "host2tcl-input-ring3", "host2tcl-input-ring2", "host2tcl-input-ring1", "wbm2host-tx-completions-ring3", "wbm2host-tx-completions-ring2", "wbm2host-tx-completions-ring1", "tcl2host-status-ring";
			status = "ok";
			qcom,pta-num = <0x00>;
			qcom,coex-mode = <0x02>;
			qcom,bt-active-time = <0x18>;
			qcom,bt-priority-time = <0x12>;
			qcom,coex-algo = <0x02>;
			qcom,pta-priority = <0x80800505>;
			qcom,board_id = <0x13>;
		};

		qcom,msm-imem@8600000 {
			compatible = "qcom,msm-imem";
			reg = <0x8600000 0x1000>;
			ranges = <0x00 0x8600000 0x1000>;
			#address-cells = <0x01>;
			#size-cells = <0x01>;

			mem_dump_table@10 {
				compatible = "qcom,msm-imem-mem_dump_table";
				reg = <0x10 0x08>;
			};
		};

		qca,scm_restart_reason {
			compatible = "qca_ipq6018,scm_restart_reason";
			reg = <0x193d000 0x14>;
		};

		slim@a2c0000 {
			cell-index = <0x01>;
			compatible = "qcom,slim-ngd";
			reg = <0xa2c0000 0x2c000 0xa284000 0x2a000>;
			reg-names = "slimbus_physical", "slimbus_bam_physical";
			interrupts = <0x00 0x1f 0x00 0x00 0x20 0x00>;
			interrupt-names = "slimbus_irq", "slimbus_bam_irq";
			qcom,apps-ch-pipes = <0x7c0000>;
			qcom,ea-pc = <0x320>;
			status = "disabled";
		};

		qca,tzlog {
			compatible = "qca,tzlog_ipq6018";
			interrupts = <0x00 0xf4 0x01>;
			qca,tzbsp-diag-buf-start = <0x4a7df000>;
			qca,tzbsp-diag-buf-size = <0x3000>;
			qca,hyp-enabled;
			hyp-scm-cmd-id = <0x0a>;
		};

		qcom,rpm-log@29fc00 {
			compatible = "qcom,rpm-log";
			reg = <0x29fc00 0x4000>;
			qcom,rpm-addr-phys = <0x200000>;
			qcom,offset-version = <0x04>;
			qcom,offset-page-buffer-addr = <0x24>;
			qcom,offset-log-len = <0x28>;
			qcom,offset-log-len-mask = <0x2c>;
			qcom,offset-page-indices = <0x38>;
		};

		qcom,test@0 {
			compatible = "qcom,testmhi";
			status = "ok";
		};

		tmc@6048000 {
			compatible = "arm,primecell";
			arm,primecell-periphid = <0x3b961>;
			reg = <0x6048000 0x1000 0x6064000 0x15000>;
			reg-names = "tmc-base", "bam-base";
			interrupts = <0x00 0xa6 0x00>;
			interrupt-names = "byte-cntr-irq";
			memory_region = <0x1e>;
			arm,buffer-size = <0x100000>;
			arm,sg-enable;
			coresight-ctis = <0x2d 0x2e>;
			coresight-name = "coresight-tmc-etr";
			clocks = <0x03 0xbf 0x03 0xbe>;
			clock-names = "apb_pclk", "core_a_clk";

			port {

				endpoint {
					slave-mode;
					remote-endpoint = <0x2f>;
					linux,phandle = <0x30>;
					phandle = <0x30>;
				};
			};
		};

		replicator@6046000 {
			compatible = "arm,primecell";
			arm,primecell-periphid = <0x3b909>;
			reg = <0x6046000 0x1000>;
			reg-names = "replicator-base";
			coresight-name = "coresight-replicator";
			clocks = <0x03 0xbf 0x03 0xbe>;
			clock-names = "apb_pclk", "core_a_clk";

			ports {
				#address-cells = <0x01>;
				#size-cells = <0x00>;

				port@0 {
					reg = <0x00>;

					endpoint {
						remote-endpoint = <0x30>;
						linux,phandle = <0x2f>;
						phandle = <0x2f>;
					};
				};

				port@1 {
					reg = <0x00>;

					endpoint {
						slave-mode;
						remote-endpoint = <0x31>;
						linux,phandle = <0x32>;
						phandle = <0x32>;
					};
				};
			};
		};

		tmc@6047000 {
			compatible = "arm,primecell";
			arm,primecell-periphid = <0x3b961>;
			reg = <0x6047000 0x1000>;
			reg-names = "tmc-base";
			coresight-ctis = <0x2d 0x2e>;
			coresight-name = "coresight-tmc-etf";
			arm,default-sink;
			clocks = <0x03 0xbf 0x03 0xbe>;
			clock-names = "apb_pclk", "core_a_clk";

			ports {
				#address-cells = <0x01>;
				#size-cells = <0x00>;

				port@0 {
					reg = <0x00>;

					endpoint {
						remote-endpoint = <0x32>;
						linux,phandle = <0x31>;
						phandle = <0x31>;
					};
				};

				port@1 {
					reg = <0x00>;

					endpoint {
						slave-mode;
						remote-endpoint = <0x33>;
						linux,phandle = <0x34>;
						phandle = <0x34>;
					};
				};
			};
		};

		funnel@6041000 {
			compatible = "arm,primecell";
			arm,primecell-periphid = <0x3b908>;
			reg = <0x6041000 0x1000>;
			reg-names = "funnel-base";
			coresight-name = "coresight-funnel-in0";
			clocks = <0x03 0xbf 0x03 0xbe>;
			clock-names = "apb_pclk", "core_a_clk";

			ports {
				#address-cells = <0x01>;
				#size-cells = <0x00>;

				port@0 {
					reg = <0x00>;

					endpoint {
						remote-endpoint = <0x34>;
						linux,phandle = <0x33>;
						phandle = <0x33>;
					};
				};

				port@1 {
					reg = <0x03>;

					endpoint {
						slave-mode;
						remote-endpoint = <0x35>;
						linux,phandle = <0x3b>;
						phandle = <0x3b>;
					};
				};

				port@2 {
					reg = <0x04>;

					endpoint {
						slave-mode;
						remote-endpoint = <0x36>;
						linux,phandle = <0x3e>;
						phandle = <0x3e>;
					};
				};

				port@3 {
					reg = <0x05>;

					endpoint {
						slave-mode;
						remote-endpoint = <0x37>;
						linux,phandle = <0x3d>;
						phandle = <0x3d>;
					};
				};

				port@4 {
					reg = <0x06>;

					endpoint {
						slave-mode;
						remote-endpoint = <0x38>;
						linux,phandle = <0x50>;
						phandle = <0x50>;
					};
				};

				port@5 {
					reg = <0x07>;

					endpoint {
						slave-mode;
						remote-endpoint = <0x39>;
						linux,phandle = <0x4e>;
						phandle = <0x4e>;
					};
				};

				port@6 {
					reg = <0x00>;

					endpoint {
						slave-mode;
						remote-endpoint = <0x3a>;
						linux,phandle = <0x4d>;
						phandle = <0x4d>;
					};
				};
			};
		};

		funnel@6100000 {
			compatible = "arm,primecell";
			arm,primecell-periphid = <0x3b908>;
			reg = <0x6100000 0x1000>;
			reg-names = "funnel-base";
			coresight-name = "coresight-funnel-center";
			clocks = <0x03 0xbf 0x03 0xbe>;
			clock-names = "apb_pclk", "core_a_clk";

			ports {
				#address-cells = <0x01>;
				#size-cells = <0x00>;

				port@0 {
					reg = <0x00>;

					endpoint {
						remote-endpoint = <0x3b>;
						linux,phandle = <0x35>;
						phandle = <0x35>;
					};
				};

				port@1 {
					reg = <0x02>;

					endpoint {
						slave-mode;
						remote-endpoint = <0x3c>;
						linux,phandle = <0x4f>;
						phandle = <0x4f>;
					};
				};
			};
		};

		funnel@6130000 {
			compatible = "arm,primecell";
			arm,primecell-periphid = <0x3b908>;
			reg = <0x6130000 0x1000>;
			reg-names = "funnel-base";
			coresight-name = "coresight-funnel-mm";
			clocks = <0x03 0xbf 0x03 0xbe>;
			clock-names = "apb_pclk", "core_a_clk";

			ports {
				#address-cells = <0x01>;
				#size-cells = <0x00>;

				port@0 {
					reg = <0x00>;

					endpoint {
						remote-endpoint = <0x3d>;
						linux,phandle = <0x37>;
						phandle = <0x37>;
					};
				};
			};
		};

		funnel@6120000 {
			compatible = "arm,primecell";
			arm,primecell-periphid = <0x3b908>;
			reg = <0x6120000 0x1000>;
			reg-names = "funnel-base";
			coresight-name = "coresight-funnel-right";
			clocks = <0x03 0xbf 0x03 0xbe>;
			clock-names = "apb_pclk", "core_a_clk";

			ports {
				#address-cells = <0x01>;
				#size-cells = <0x00>;

				port@0 {
					reg = <0x00>;

					endpoint {
						remote-endpoint = <0x3e>;
						linux,phandle = <0x36>;
						phandle = <0x36>;
					};
				};

				port@1 {
					reg = <0x03>;

					endpoint {
						slave-mode;
						remote-endpoint = <0x3f>;
						linux,phandle = <0x40>;
						phandle = <0x40>;
					};
				};
			};
		};

		funnel@61a1000 {
			compatible = "arm,primecell";
			arm,primecell-periphid = <0x3b908>;
			reg = <0x61a1000 0x1000>;
			reg-names = "funnel-base";
			coresight-name = "coresight-funnel-apss0";
			clocks = <0x03 0xbf 0x03 0xbe>;
			clock-names = "apb_pclk", "core_a_clk";

			ports {
				#address-cells = <0x01>;
				#size-cells = <0x00>;

				port@0 {
					reg = <0x00>;

					endpoint {
						remote-endpoint = <0x40>;
						linux,phandle = <0x3f>;
						phandle = <0x3f>;
					};
				};

				port@1 {
					reg = <0x00>;

					endpoint {
						slave-mode;
						remote-endpoint = <0x41>;
						linux,phandle = <0x46>;
						phandle = <0x46>;
					};
				};

				port@2 {
					reg = <0x01>;

					endpoint {
						slave-mode;
						remote-endpoint = <0x42>;
						linux,phandle = <0x48>;
						phandle = <0x48>;
					};
				};

				port@3 {
					reg = <0x02>;

					endpoint {
						slave-mode;
						remote-endpoint = <0x43>;
						linux,phandle = <0x4a>;
						phandle = <0x4a>;
					};
				};

				port@4 {
					reg = <0x03>;

					endpoint {
						slave-mode;
						remote-endpoint = <0x44>;
						linux,phandle = <0x4c>;
						phandle = <0x4c>;
					};
				};
			};
		};

		etm@619c000 {
			compatible = "arm,primecell";
			arm,primecell-periphid = <0x3b95d>;
			reg = <0x619c000 0x1000>;
			coresight-name = "coresight-etm0";
			cpu = <0x45>;
			clocks = <0x03 0xbf 0x03 0xbe>;
			clock-names = "apb_pclk", "core_a_clk";

			port {

				endpoint {
					remote-endpoint = <0x46>;
					linux,phandle = <0x41>;
					phandle = <0x41>;
				};
			};
		};

		etm@619d000 {
			compatible = "arm,primecell";
			arm,primecell-periphid = <0x3b95d>;
			reg = <0x619d000 0x1000>;
			coresight-name = "coresight-etm1";
			cpu = <0x47>;
			clocks = <0x03 0xbf 0x03 0xbe>;
			clock-names = "apb_pclk", "core_a_clk";

			port {

				endpoint {
					remote-endpoint = <0x48>;
					linux,phandle = <0x42>;
					phandle = <0x42>;
				};
			};
		};

		etm@619e000 {
			compatible = "arm,primecell";
			arm,primecell-periphid = <0x3b95d>;
			reg = <0x619e000 0x1000>;
			coresight-name = "coresight-etm2";
			cpu = <0x49>;
			clocks = <0x03 0xbf 0x03 0xbe>;
			clock-names = "apb_pclk", "core_a_clk";

			port {

				endpoint {
					remote-endpoint = <0x4a>;
					linux,phandle = <0x43>;
					phandle = <0x43>;
				};
			};
		};

		etm@619f000 {
			compatible = "arm,primecell";
			arm,primecell-periphid = <0x3b95d>;
			reg = <0x619f000 0x1000>;
			coresight-name = "coresight-etm3";
			cpu = <0x4b>;
			clocks = <0x03 0xbf 0x03 0xbe>;
			clock-names = "apb_pclk", "core_a_clk";

			port {

				endpoint {
					remote-endpoint = <0x4c>;
					linux,phandle = <0x44>;
					phandle = <0x44>;
				};
			};
		};

		rpm_etm0 {
			compatible = "qcom,coresight-remote-etm";
			coresight-name = "coresight-rpm-etm0";
			qcom,inst-id = <0x04>;

			port {

				endpoint {
					remote-endpoint = <0x4d>;
					linux,phandle = <0x3a>;
					phandle = <0x3a>;
				};
			};
		};

		stm@6002000 {
			compatible = "arm,primecell";
			arm,primecell-periphid = <0x3b962>;
			reg = <0x6002000 0x1000 0x9280000 0x180000>;
			reg-names = "stm-base", "stm-data-base";
			coresight-name = "coresight-stm";
			clocks = <0x03 0xbf 0x03 0xbe>;
			clock-names = "apb_pclk", "core_a_clk";

			port {

				endpoint {
					remote-endpoint = <0x4e>;
					linux,phandle = <0x39>;
					phandle = <0x39>;
				};
			};
		};

		cti@6010000 {
			compatible = "arm,coresight-cti";
			reg = <0x6010000 0x1000>;
			reg-names = "cti-base";
			coresight-name = "coresight-cti0";
			clocks = <0x03 0xbf 0x03 0xbe>;
			clock-names = "core_clk", "core_a_clk";
			linux,phandle = <0x2d>;
			phandle = <0x2d>;
		};

		cti@6011000 {
			compatible = "arm,coresight-cti";
			reg = <0x6011000 0x1000>;
			reg-names = "cti-base";
			coresight-name = "coresight-cti1";
			clocks = <0x03 0xbf 0x03 0xbe>;
			clock-names = "core_clk", "core_a_clk";
		};

		cti@6012000 {
			compatible = "arm,coresight-cti";
			reg = <0x6012000 0x1000>;
			reg-names = "cti-base";
			coresight-name = "coresight-cti2";
			clocks = <0x03 0xbf 0x03 0xbe>;
			clock-names = "core_clk", "core_a_clk";
		};

		cti@6013000 {
			compatible = "arm,coresight-cti";
			reg = <0x6013000 0x1000>;
			reg-names = "cti-base";
			coresight-name = "coresight-cti3";
			clocks = <0x03 0xbf 0x03 0xbe>;
			clock-names = "core_clk", "core_a_clk";
		};

		cti@6014000 {
			compatible = "arm,coresight-cti";
			reg = <0x6014000 0x1000>;
			reg-names = "cti-base";
			coresight-name = "coresight-cti4";
			clocks = <0x03 0xbf 0x03 0xbe>;
			clock-names = "core_clk", "core_a_clk";
		};

		cti@6015000 {
			compatible = "arm,coresight-cti";
			reg = <0x6015000 0x1000>;
			reg-names = "cti-base";
			coresight-name = "coresight-cti5";
			clocks = <0x03 0xbf 0x03 0xbe>;
			clock-names = "core_clk", "core_a_clk";
		};

		cti@6016000 {
			compatible = "arm,coresight-cti";
			reg = <0x6016000 0x1000>;
			reg-names = "cti-base";
			coresight-name = "coresight-cti6";
			clocks = <0x03 0xbf 0x03 0xbe>;
			clock-names = "core_clk", "core_a_clk";
		};

		cti@6017000 {
			compatible = "arm,coresight-cti";
			reg = <0x6017000 0x1000>;
			reg-names = "cti-base";
			coresight-name = "coresight-cti7";
			clocks = <0x03 0xbf 0x03 0xbe>;
			clock-names = "core_clk", "core_a_clk";
		};

		cti@6018000 {
			compatible = "arm,coresight-cti";
			reg = <0x6018000 0x1000>;
			reg-names = "cti-base";
			coresight-name = "coresight-cti8";
			clocks = <0x03 0xbf 0x03 0xbe>;
			clock-names = "core_clk", "core_a_clk";
			linux,phandle = <0x2e>;
			phandle = <0x2e>;
		};

		cti@6019000 {
			compatible = "arm,coresight-cti";
			reg = <0x6019000 0x1000>;
			reg-names = "cti-base";
			coresight-name = "coresight-cti9";
			clocks = <0x03 0xbf 0x03 0xbe>;
			clock-names = "core_clk", "core_a_clk";
		};

		cti@601a000 {
			compatible = "arm,coresight-cti";
			reg = <0x601a000 0x1000>;
			reg-names = "cti-base";
			coresight-name = "coresight-cti10";
			clocks = <0x03 0xbf 0x03 0xbe>;
			clock-names = "core_clk", "core_a_clk";
		};

		cti@601b000 {
			compatible = "arm,coresight-cti";
			reg = <0x601b000 0x1000>;
			reg-names = "cti-base";
			coresight-name = "coresight-cti11";
			clocks = <0x03 0xbf 0x03 0xbe>;
			clock-names = "core_clk", "core_a_clk";
		};

		cti@601c000 {
			compatible = "arm,coresight-cti";
			reg = <0x601c000 0x1000>;
			reg-names = "cti-base";
			coresight-name = "coresight-cti12";
			clocks = <0x03 0xbf 0x03 0xbe>;
			clock-names = "core_clk", "core_a_clk";
		};

		cti@601d000 {
			compatible = "arm,coresight-cti";
			reg = <0x601d000 0x1000>;
			reg-names = "cti-base";
			coresight-name = "coresight-cti13";
			clocks = <0x03 0xbf 0x03 0xbe>;
			clock-names = "core_clk", "core_a_clk";
		};

		cti@601e000 {
			compatible = "arm,coresight-cti";
			reg = <0x601e000 0x1000>;
			reg-names = "cti-base";
			coresight-name = "coresight-cti14";
			clocks = <0x03 0xbf 0x03 0xbe>;
			clock-names = "core_clk", "core_a_clk";
		};

		cti@601f000 {
			compatible = "arm,coresight-cti";
			reg = <0x601f000 0x1000>;
			reg-names = "cti-base";
			coresight-name = "coresight-cti15";
			clocks = <0x03 0xbf 0x03 0xbe>;
			clock-names = "core_clk", "core_a_clk";
		};

		cti@6198000 {
			compatible = "arm,coresight-cti";
			reg = <0x6198000 0x1000>;
			reg-names = "cti-base";
			coresight-name = "coresight-cti-cpu0";
			cpu = <0x45>;
			clocks = <0x03 0xbf 0x03 0xbe>;
			clock-names = "core_clk", "core_a_clk";
		};

		cti@6199000 {
			compatible = "arm,coresight-cti";
			reg = <0x6199000 0x1000>;
			reg-names = "cti-base";
			coresight-name = "coresight-cti-cpu1";
			cpu = <0x47>;
			clocks = <0x03 0xbf 0x03 0xbe>;
			clock-names = "core_clk", "core_a_clk";
		};

		cti@619a000 {
			compatible = "arm,coresight-cti";
			reg = <0x619a000 0x1000>;
			reg-names = "cti-base";
			coresight-name = "coresight-cti-cpu2";
			cpu = <0x49>;
			clocks = <0x03 0xbf 0x03 0xbe>;
			clock-names = "core_clk", "core_a_clk";
		};

		cti@619b000 {
			compatible = "arm,coresight-cti";
			reg = <0x619b000 0x1000>;
			reg-names = "cti-base";
			coresight-name = "coresight-cti-cpu3";
			cpu = <0x4b>;
			clocks = <0x03 0xbf 0x03 0xbe>;
			clock-names = "core_clk", "core_a_clk";
		};

		cti@610c000 {
			compatible = "arm,coresight-cti";
			reg = <0x610c000 0x1000>;
			reg-names = "cti-base";
			coresight-name = "coresight-cti-rpm-cpu0";
			clocks = <0x03 0xbf 0x03 0xbe>;
			clock-names = "core_clk", "core_a_clk";
		};

		csr@6001000 {
			compatible = "qcom,coresight-csr";
			reg = <0x6001000 0x1000>;
			reg-names = "csr-base";
			coresight-name = "coresight-csr";
			qcom,blk-size = <0x01>;
			clocks = <0x03 0xbf 0x03 0xbe>;
			clock-names = "core_clk", "core_a_clk";
		};

		dbgui@6108000 {
			compatible = "qcom,coresight-dbgui";
			reg = <0x6108000 0x1000>;
			reg-names = "dbgui-base";
			coresight-name = "coresight-dbgui";
			qcom,dbgui-addr-offset = <0x30>;
			qcom,dbgui-data-offset = <0x130>;
			qcom,dbgui-size = <0x40>;
			clocks = <0x03 0xbf 0x03 0xbe>;
			clock-names = "core_clk", "core_a_clk";

			port {

				endpoint {
					remote-endpoint = <0x4f>;
					linux,phandle = <0x3c>;
					phandle = <0x3c>;
				};
			};
		};

		tpda@6004000 {
			compatible = "qcom,coresight-tpda";
			reg = <0x6004000 0x1000>;
			reg-names = "tpda-base";
			coresight-name = "coresight-tpda";
			qcom,tpda-atid = <0x40>;
			qcom,cmb-elem-size = <0x00 0x20>;
			clocks = <0x03 0xbf 0x03 0xbe>;
			clock-names = "core_clk", "core_a_clk";

			ports {
				#address-cells = <0x01>;
				#size-cells = <0x00>;

				port@0 {
					reg = <0x00>;

					endpoint {
						remote-endpoint = <0x50>;
						linux,phandle = <0x38>;
						phandle = <0x38>;
					};
				};

				port@1 {
					reg = <0x00>;

					endpoint {
						slave-mode;
						remote-endpoint = <0x51>;
						linux,phandle = <0x52>;
						phandle = <0x52>;
					};
				};
			};
		};

		tpdm@6110000 {
			compatible = "qcom,coresight-tpdm";
			reg = <0x6110000 0x1000>;
			reg-names = "tpdm-base";
			coresight-name = "coresight-tpdm-dcc";
			clocks = <0x03 0xbf 0x03 0xbe>;
			clock-names = "core_clk", "core_a_clk";

			port {

				endpoint {
					remote-endpoint = <0x52>;
					linux,phandle = <0x51>;
					phandle = <0x51>;
				};
			};
		};

		hwevent@6101000 {
			compatible = "qcom,coresight-hwevent";
			reg = <0x6101000 0x148 0x6101fb0 0x04 0x6121000 0x148 0x6121fb0 0x04 0x6131000 0x148 0x6131fb0 0x04 0x6130fb0 0x04 0x6130000 0x148 0x6041fb0 0x04 0x6041000 0x148>;
			reg-names = "center-wrapper-mux", "center-wrapper-lockaccess", "right-wrapper-mux", "right-wrapper-lockaccess", "mm-wrapper-mux", "mm-wrapper-lockaccess", "mm-fun-lockaccess", "mm-fun", "in-fun-lockaccess", "in-fun";
			coresight-name = "coresight-hwevent";
			clocks = <0x03 0xbf 0x03 0xbe>;
			clock-names = "core_clk", "core_a_clk";
		};

		thermal-sensor@4a8000 {
			compatible = "qcom,ipq6018-tsens";
			reg = <0x4a8000 0x2000>;
			interrupts = <0x00 0xb8 0x00>;
			#thermal-sensor-cells = <0x01>;
			tsens-up-low-int-clr-deassert-quirk;
			status = "ok";
			linux,phandle = <0x5c>;
			phandle = <0x5c>;
		};

		dp1 {
			device_type = "network";
			compatible = "qcom,nss-dp";
			qcom,id = <0x04>;
			reg = <0x3a001600 0x200>;
			qcom,mactype = <0x00>;
			local-mac-address = [00 00 00 00 00 00];
			qcom,link-poll = <0x01>;
			qcom,phy-mdio-addr = <0x10>;
			phy-mode = "sgmii";
		};

		dp2 {
			device_type = "network";
			compatible = "qcom,nss-dp";
			qcom,id = <0x05>;
			reg = <0x3a001800 0x200>;
			qcom,mactype = <0x00>;
			local-mac-address = [00 00 00 00 00 00];
			qcom,link-poll = <0x01>;
			qcom,phy-mdio-addr = <0x14>;
			phy-mode = "sgmii";
		};

		nss-macsec0 {
			compatible = "qcom,nss-macsec";
			phy_addr = <0x10>;
			phy_access_mode = <0x00>;
			mdiobus = <0x53>;
		};

		nss-macsec1 {
			compatible = "qcom,nss-macsec";
			phy_addr = <0x14>;
			phy_access_mode = <0x00>;
			mdiobus = <0x53>;
		};

		gpio_keys {
			compatible = "gpio-keys";
			pinctrl-0 = <0x54>;
			pinctrl-names = "default";

			reset {
				label = "reset";
				linux,code = <0x74>;
				gpios = <0x0e 0x30 0x01>;
				linux,input-type = <0x01>;
				debounce-interval = <0x3c>;
			};
		};

		generic-gpios {
			compatible = "gpio-leds";
			pinctrl-0 = <0x25>;
			pinctrl-names = "default";

			gps_reset_pin {
				gpios = <0x0e 0x16 0x00>;
				default-state = "on";
			};

			bt_mcuboot {
				gpios = <0x0e 0x0f 0x01>;
				default-state = "off";
			};

			bt_reset {
				gpios = <0x0e 0x2b 0x01>;
				default-state = "on";
			};

			usb_en {
				gpios = <0x0e 0x43 0x00>;
				default-state = "on";
			};
		};

		leds {
			compatible = "gpio-leds";
			pinctrl-0 = <0x55>;
			pinctrl-names = "default";

			led@0 {
				label = "ipq::led0";
				gpios = <0x0e 0x00 0x00>;
				linux,default-trigger = "lan1_g_led";
				default-state = "off";
			};

			led@1 {
				label = "ipq::led1";
				gpios = <0x0e 0x01 0x00>;
				linux,default-trigger = "lan1_r_led";
				default-state = "off";
			};

			led@4 {
				label = "ipq::led4";
				gpios = <0x0e 0x04 0x00>;
				linux,default-trigger = "lan0_g_led";
				default-state = "off";
			};

			led@5 {
				label = "ipq::led5";
				gpios = <0x0e 0x05 0x00>;
				linux,default-trigger = "lan0_r_led";
				default-state = "off";
			};

			led@6 {
				label = "ipq::led6";
				gpios = <0x0e 0x06 0x00>;
				linux,default-trigger = "6g_g_led";
				default-state = "off";
			};

			led@7 {
				label = "ipq::led7";
				gpios = <0x0e 0x07 0x00>;
				linux,default-trigger = "6g_r_led";
				default-state = "off";
			};

			led@8 {
				label = "ipq::led8";
				gpios = <0x0e 0x08 0x00>;
				linux,default-trigger = "5g_g_led";
				default-state = "off";
			};

			led@9 {
				label = "ipq::led9";
				gpios = <0x0e 0x09 0x00>;
				linux,default-trigger = "5g_r_led";
				default-state = "off";
			};

			led@11 {
				label = "ipq::led11";
				gpios = <0x0e 0x0b 0x00>;
				linux,default-trigger = "2g_g_led";
				default-state = "off";
			};

			led@12 {
				label = "ipq::led12";
				gpios = <0x0e 0x0c 0x00>;
				linux,default-trigger = "2g_r_led";
				default-state = "off";
			};

			led@13 {
				label = "ipq::led13";
				gpios = <0x0e 0x0d 0x00>;
				linux,default-trigger = "pwr_g_led";
				default-state = "off";
			};

			led@14 {
				label = "ipq::led14";
				gpios = <0x0e 0x0e 0x00>;
				linux,default-trigger = "pwr_r_led";
				default-state = "on";
			};
		};
	};

	psci {
		compatible = "arm,psci-1.0";
		method = "smc";
		status = "ok";
	};

	cpus {
		#address-cells = <0x01>;
		#size-cells = <0x00>;

		cpu@0 {
			device_type = "cpu";
			compatible = "arm,cortex-a53", "arm,armv8";
			reg = <0x00>;
			enable-method = "psci";
			qcom,acc = <0x56>;
			next-level-cache = <0x57>;
			clocks = <0x58 0x03>;
			clock-names = "cpu";
			operating-points = <0xd2f00 0x10c8e0 0x101d00 0x10c8e0 0x142440 0x10c8e0 0x15f900 0x10c8e0 0x188940 0x10c8e0 0x1b7740 0x10c8e0>;
			clock-latency = <0x30d40>;
			linux,phandle = <0x45>;
			phandle = <0x45>;

			l2-cache {
				compatible = "cache";
				cache-level = <0x02>;
				linux,phandle = <0x57>;
				phandle = <0x57>;
			};
		};

		cpu@1 {
			device_type = "cpu";
			compatible = "arm,cortex-a53", "arm,armv8";
			enable-method = "psci";
			qcom,acc = <0x59>;
			reg = <0x01>;
			next-level-cache = <0x57>;
			clocks = <0x58 0x03>;
			clock-names = "cpu";
			operating-points = <0xd2f00 0x10c8e0 0x101d00 0x10c8e0 0x142440 0x10c8e0 0x15f900 0x10c8e0 0x188940 0x10c8e0 0x1b7740 0x10c8e0>;
			clock-latency = <0x30d40>;
			linux,phandle = <0x47>;
			phandle = <0x47>;
		};

		cpu@2 {
			device_type = "cpu";
			compatible = "arm,cortex-a53", "arm,armv8";
			enable-method = "psci";
			qcom,acc = <0x5a>;
			reg = <0x02>;
			next-level-cache = <0x57>;
			clocks = <0x58 0x03>;
			clock-names = "cpu";
			operating-points = <0xd2f00 0x10c8e0 0x101d00 0x10c8e0 0x142440 0x10c8e0 0x15f900 0x10c8e0 0x188940 0x10c8e0 0x1b7740 0x10c8e0>;
			clock-latency = <0x30d40>;
			linux,phandle = <0x49>;
			phandle = <0x49>;
		};

		cpu@3 {
			device_type = "cpu";
			compatible = "arm,cortex-a53", "arm,armv8";
			enable-method = "psci";
			qcom,acc = <0x5b>;
			reg = <0x03>;
			next-level-cache = <0x57>;
			clocks = <0x58 0x03>;
			clock-names = "cpu";
			operating-points = <0xd2f00 0x10c8e0 0x101d00 0x10c8e0 0x142440 0x10c8e0 0x15f900 0x10c8e0 0x188940 0x10c8e0 0x1b7740 0x10c8e0>;
			clock-latency = <0x30d40>;
			linux,phandle = <0x4b>;
			phandle = <0x4b>;
		};
	};

	qseecom {
		compatible = "ipq6018-qseecom";
		status = "ok";
		mem-start = <0x49b00000>;
		mem-size = <0x600000>;
	};

	firmware {

		scm {
			compatible = "qcom,scm-ipq6018";
			smmu-state-scm-cmd-id = <0x20>;
		};

		qfprom_sec {
			compatible = "qcom,qfprom-sec";
			img-addr = <0x4a100000>;
			img-size = <0x500000>;
			scm-cmd-id = <0x1f>;
		};
	};

	pmu {
		compatible = "arm,cortex-a53-pmu";
		interrupts = <0x01 0x07 0xf04>;
	};

	clocks {

		sleep_clk {
			compatible = "fixed-clock";
			clock-frequency = <0x7d00>;
			#clock-cells = <0x00>;
			linux,phandle = <0x27>;
			phandle = <0x27>;
		};

		xo {
			compatible = "fixed-clock";
			clock-frequency = <0x16e3600>;
			#clock-cells = <0x00>;
		};

		bias_pll_cc_clk {
			compatible = "fixed-clock";
			clock-frequency = <0x11e1a300>;
			#clock-cells = <0x00>;
		};

		bias_pll_nss_noc_clk {
			compatible = "fixed-clock";
			clock-frequency = <0x18d34920>;
			#clock-cells = <0x00>;
		};

		usb3phy_0_cc_pipe_clk {
			compatible = "fixed-clock";
			clock-frequency = <0x7735940>;
			#clock-cells = <0x00>;
		};
	};

	ion_dummy {
		compatible = "ipq60xx-ion-dummy";
		status = "disabled";
	};

	thermal-zones {

		tsens_tz_sensor4 {
			polling-delay-passive = <0x00>;
			polling-delay = <0x00>;
			thermal-sensors = <0x5c 0x04>;

			trips {

				cpu-critical-hi {
					temperature = <0x7d>;
					hysteresis = <0x02>;
					type = "critical_high";
				};

				cpu-config-hi {
					temperature = <0x69>;
					hysteresis = <0x02>;
					type = "configurable_hi";
				};

				cpu-config-lo {
					temperature = <0x5f>;
					hysteresis = <0x02>;
					type = "configurable_lo";
				};

				cpu-critical-low {
					temperature = <0x00>;
					hysteresis = <0x02>;
					type = "critical_low";
				};
			};
		};

		tsens_tz_sensor5 {
			polling-delay-passive = <0x00>;
			polling-delay = <0x00>;
			thermal-sensors = <0x5c 0x05>;

			trips {

				cpu-critical-hi {
					temperature = <0x7d>;
					hysteresis = <0x02>;
					type = "critical_high";
				};

				cpu-config-hi {
					temperature = <0x69>;
					hysteresis = <0x02>;
					type = "configurable_hi";
				};

				cpu-config-lo {
					temperature = <0x5f>;
					hysteresis = <0x02>;
					type = "configurable_lo";
				};

				cpu-critical-low {
					temperature = <0x00>;
					hysteresis = <0x02>;
					type = "critical_low";
				};
			};
		};

		tsens_tz_sensor7 {
			polling-delay-passive = <0x00>;
			polling-delay = <0x00>;
			thermal-sensors = <0x5c 0x07>;

			trips {

				cpu-critical-hi {
					temperature = <0x7d>;
					hysteresis = <0x02>;
					type = "critical_high";
				};

				cpu-config-hi {
					temperature = <0x69>;
					hysteresis = <0x02>;
					type = "configurable_hi";
				};

				cpu-config-lo {
					temperature = <0x5f>;
					hysteresis = <0x02>;
					type = "configurable_lo";
				};

				cpu-critical-low {
					temperature = <0x00>;
					hysteresis = <0x02>;
					type = "critical_low";
				};
			};
		};

		tsens_tz_sensor8 {
			polling-delay-passive = <0x00>;
			polling-delay = <0x00>;
			thermal-sensors = <0x5c 0x08>;

			trips {

				cpu-critical-hi {
					temperature = <0x7d>;
					hysteresis = <0x02>;
					type = "critical_high";
				};

				cpu-config-hi {
					temperature = <0x69>;
					hysteresis = <0x02>;
					type = "configurable_hi";
				};

				cpu-config-lo {
					temperature = <0x5f>;
					hysteresis = <0x02>;
					type = "configurable_lo";
				};

				cpu-critical-low {
					temperature = <0x00>;
					hysteresis = <0x02>;
					type = "critical_low";
				};
			};
		};

		tsens_tz_sensor13 {
			polling-delay-passive = <0x00>;
			polling-delay = <0x00>;
			thermal-sensors = <0x5c 0x0d>;

			trips {

				cpu-critical-hi {
					temperature = <0x7d>;
					hysteresis = <0x02>;
					type = "critical_high";
				};

				cpu-config-hi {
					temperature = <0x69>;
					hysteresis = <0x02>;
					type = "configurable_hi";
				};

				cpu-config-lo {
					temperature = <0x5f>;
					hysteresis = <0x02>;
					type = "configurable_lo";
				};

				cpu-critical-low {
					temperature = <0x00>;
					hysteresis = <0x02>;
					type = "critical_low";
				};
			};
		};

		tsens_tz_sensor14 {
			polling-delay-passive = <0x00>;
			polling-delay = <0x00>;
			thermal-sensors = <0x5c 0x0e>;

			trips {

				cpu-critical-hi {
					temperature = <0x7d>;
					hysteresis = <0x02>;
					type = "critical_high";
				};

				cpu-config-hi {
					temperature = <0x69>;
					hysteresis = <0x02>;
					type = "configurable_hi";
				};

				cpu-config-lo {
					temperature = <0x5f>;
					hysteresis = <0x02>;
					type = "configurable_lo";
				};

				cpu-critical-low {
					temperature = <0x00>;
					hysteresis = <0x02>;
					type = "critical_low";
				};
			};
		};

		tsens_tz_sensor15 {
			polling-delay-passive = <0x00>;
			polling-delay = <0x00>;
			thermal-sensors = <0x5c 0x0f>;

			trips {

				cpu-critical-hi {
					temperature = <0x7d>;
					hysteresis = <0x02>;
					type = "critical_high";
				};

				cpu-config-hi {
					temperature = <0x69>;
					hysteresis = <0x02>;
					type = "configurable_hi";
				};

				cpu-config-lo {
					temperature = <0x5f>;
					hysteresis = <0x02>;
					type = "configurable_lo";
				};

				cpu-critical-low {
					temperature = <0x00>;
					hysteresis = <0x02>;
					type = "critical_low";
				};
			};
		};
	};

	aliases {
		serial0 = "/soc/serial@78b1000";
		serial1 = "/soc/serial@78b0000";
		serial2 = "/soc/serial@78b2000";
		sdhc1 = "/soc/sdhci@7804000";
		sdhc2 = "/soc/sdhci_sd@7804000";
		ethernet0 = "/soc/dp1";
		ethernet1 = "/soc/dp2";
		spi0 = "/soc/spi@78b9000";
	};

	chosen {
		bootargs = "console=ttyMSM0,115200,n8 rw init=/init";
		bootargs-append = " swiotlb=1 coherent_pool=2M";
	};
};
